AUTOSAR XML (schema 3.1.2)
package /Components/SWC_CoStopStart
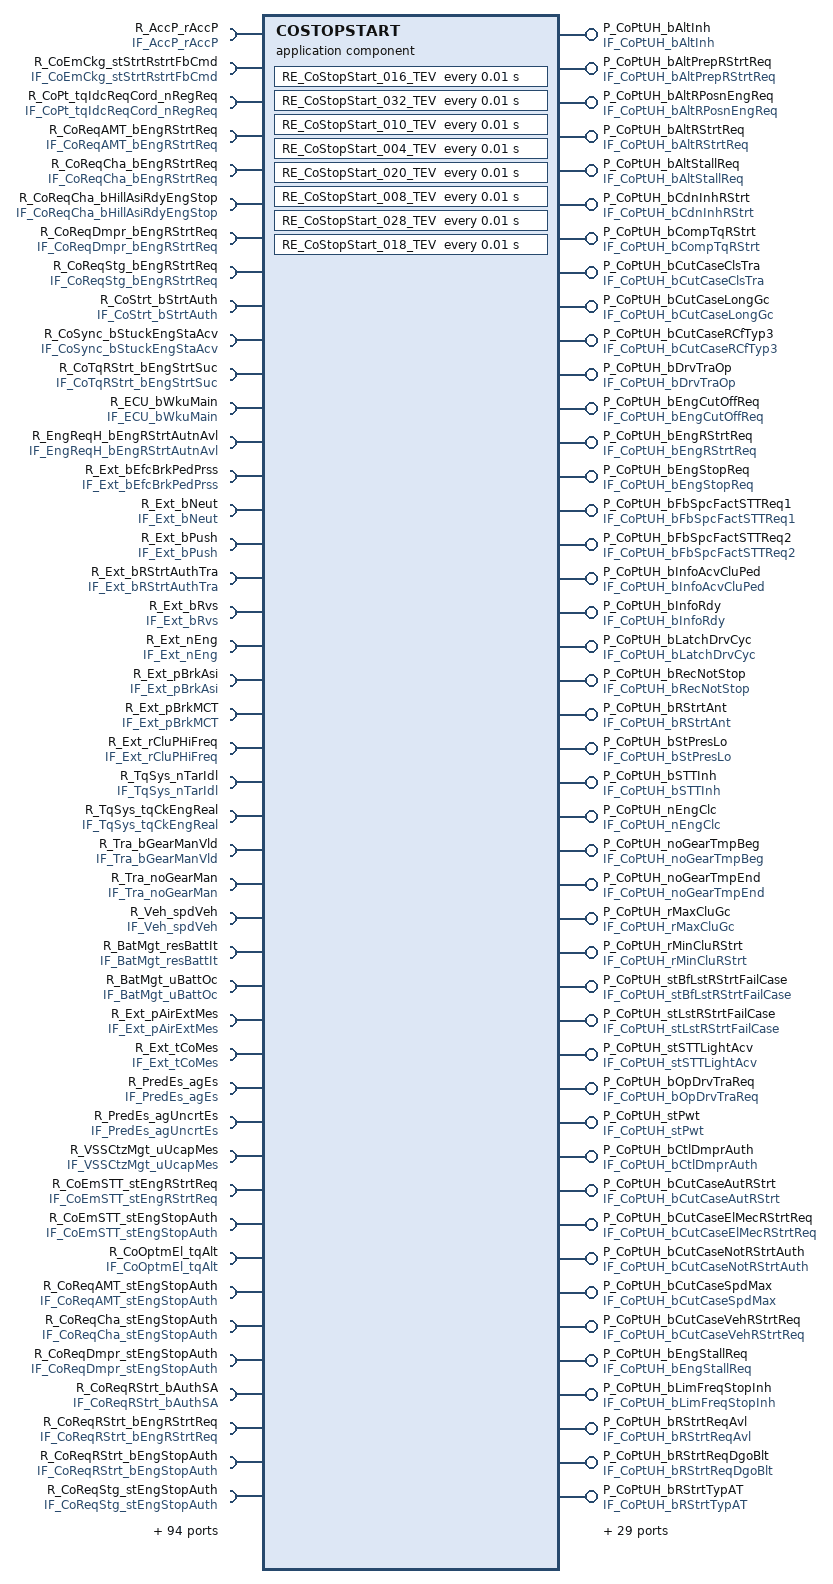
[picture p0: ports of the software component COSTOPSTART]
  application software component type COSTOPSTART
    124 x require port:
      R_AccP_rAccP: unqueued-receiver-com-spec{data-element=AccP_rAccP, init-value=ConstantValue, resync-time=0}, required-interface=IF_AccP_rAccP
      R_CoEmCkg_stStrtRstrtFbCmd: unqueued-receiver-com-spec{data-element=CoEmCkg_stStrtRstrtFbCmd, init-value=ConstantValue1, resync-time=0}, required-interface=IF_CoEmCkg_stStrtRstrtFbCmd
      R_CoPt_tqIdcReqCord_nRegReq: unqueued-receiver-com-spec{data-element=CoPt_tqIdcReqCord_nRegReq, init-value=ConstantValue3, resync-time=0}, required-interface=IF_CoPt_tqIdcReqCord_nRegReq
      R_CoReqAMT_bEngRStrtReq: unqueued-receiver-com-spec{data-element=CoReqAMT_bEngRStrtReq, init-value=CoReqAMT_bEngRStrtReq_in, resync-time=0}, required-interface=IF_CoReqAMT_bEngRStrtReq
      R_CoReqCha_bEngRStrtReq: unqueued-receiver-com-spec{data-element=CoReqCha_bEngRStrtReq, init-value=CoReqCha_bEngRStrtReq_in, resync-time=0}, required-interface=IF_CoReqCha_bEngRStrtReq
      R_CoReqCha_bHillAsiRdyEngStop: unqueued-receiver-com-spec{data-element=CoReqCha_bHillAsiRdyEngStop, init-value=CoReqCha_bHillAsiRdyEngStop_in, resync-time=0}, required-interface=IF_CoReqCha_bHillAsiRdyEngStop
      R_CoReqDmpr_bEngRStrtReq: unqueued-receiver-com-spec{data-element=CoReqDmpr_bEngRStrtReq, init-value=CoReqDmpr_bEngRStrtReq_in, resync-time=0}, required-interface=IF_CoReqDmpr_bEngRStrtReq
      R_CoReqStg_bEngRStrtReq: unqueued-receiver-com-spec{data-element=CoReqStg_bEngRStrtReq, init-value=CoReqStg_bEngRStrtReq_in, resync-time=0}, required-interface=IF_CoReqStg_bEngRStrtReq
      R_CoStrt_bStrtAuth: unqueued-receiver-com-spec{data-element=CoStrt_bStrtAuth, init-value=CoStrt_bStrtAuth_in, resync-time=0}, required-interface=IF_CoStrt_bStrtAuth
      R_CoSync_bStuckEngStaAcv: unqueued-receiver-com-spec{data-element=CoSync_bStuckEngStaAcv, init-value=CoSync_bStuckEngStaAcv_in, resync-time=0}, required-interface=IF_CoSync_bStuckEngStaAcv
      R_CoTqRStrt_bEngStrtSuc: unqueued-receiver-com-spec{data-element=CoTqRStrt_bEngStrtSuc, init-value=ConstantValue5, resync-time=0}, required-interface=IF_CoTqRStrt_bEngStrtSuc
      R_ECU_bWkuMain: unqueued-receiver-com-spec{data-element=ECU_bWkuMain, init-value=ConstantValue7, resync-time=0}, required-interface=IF_ECU_bWkuMain
      R_EngReqH_bEngRStrtAutnAvl: unqueued-receiver-com-spec{data-element=EngReqH_bEngRStrtAutnAvl, init-value=ConstantValue9, resync-time=0}, required-interface=IF_EngReqH_bEngRStrtAutnAvl
      R_Ext_bEfcBrkPedPrss: unqueued-receiver-com-spec{data-element=Ext_bEfcBrkPedPrss, init-value=Ext_bEfcBrkPedPrss_in, resync-time=0}, required-interface=IF_Ext_bEfcBrkPedPrss
      R_Ext_bNeut: unqueued-receiver-com-spec{data-element=Ext_bNeut, init-value=ConstantValue11, resync-time=0}, required-interface=IF_Ext_bNeut
      R_Ext_bPush: unqueued-receiver-com-spec{data-element=Ext_bPush, init-value=Ext_bPush_in, resync-time=0}, required-interface=IF_Ext_bPush
      R_Ext_bRStrtAuthTra: unqueued-receiver-com-spec{data-element=Ext_bRStrtAuthTra, init-value=Ext_bRStrtAuthTra_in, resync-time=0}, required-interface=IF_Ext_bRStrtAuthTra
      R_Ext_bRvs: unqueued-receiver-com-spec{data-element=Ext_bRvs, init-value=ConstantValue13, resync-time=0}, required-interface=IF_Ext_bRvs
      R_Ext_nEng: unqueued-receiver-com-spec{data-element=Ext_nEng, init-value=ConstantValue15, resync-time=0}, required-interface=IF_Ext_nEng
      R_Ext_pBrkAsi: unqueued-receiver-com-spec{data-element=Ext_pBrkAsi, init-value=Ext_pBrkAsi_in, resync-time=0}, required-interface=IF_Ext_pBrkAsi
      R_Ext_pBrkMCT: unqueued-receiver-com-spec{data-element=Ext_pBrkMCT, init-value=Ext_pBrkMCT_in, resync-time=0}, required-interface=IF_Ext_pBrkMCT
      R_Ext_rCluPHiFreq: unqueued-receiver-com-spec{data-element=Ext_rCluPHiFreq, init-value=ConstantValue17, resync-time=0}, required-interface=IF_Ext_rCluPHiFreq
      R_TqSys_nTarIdl: unqueued-receiver-com-spec{data-element=TqSys_nTarIdl, init-value=ConstantValue19, resync-time=0}, required-interface=IF_TqSys_nTarIdl
      R_TqSys_tqCkEngReal: unqueued-receiver-com-spec{data-element=TqSys_tqCkEngReal, init-value=ConstantValue21, resync-time=0}, required-interface=IF_TqSys_tqCkEngReal
      R_Tra_bGearManVld: unqueued-receiver-com-spec{data-element=Tra_bGearManVld, init-value=ConstantValue23, resync-time=0}, required-interface=IF_Tra_bGearManVld
      R_Tra_noGearMan: unqueued-receiver-com-spec{data-element=Tra_noGearMan, init-value=ConstantValue25, resync-time=0}, required-interface=IF_Tra_noGearMan
      R_Veh_spdVeh: unqueued-receiver-com-spec{data-element=Veh_spdVeh, init-value=ConstantValue27, resync-time=0}, required-interface=IF_Veh_spdVeh
      R_BatMgt_resBattIt: unqueued-receiver-com-spec{data-element=BatMgt_resBattIt, init-value=ConstantValue29, resync-time=0}, required-interface=IF_BatMgt_resBattIt
      R_BatMgt_uBattOc: unqueued-receiver-com-spec{data-element=BatMgt_uBattOc, init-value=BatMgt_uBattOc_in, resync-time=0}, required-interface=IF_BatMgt_uBattOc
      R_Ext_pAirExtMes: unqueued-receiver-com-spec{data-element=Ext_pAirExtMes, init-value=Ext_pAirExtMes_in, resync-time=0}, required-interface=IF_Ext_pAirExtMes
      R_Ext_tCoMes: unqueued-receiver-com-spec{data-element=Ext_tCoMes, init-value=ConstantValue31, resync-time=0}, required-interface=IF_Ext_tCoMes
      R_PredEs_agEs: unqueued-receiver-com-spec{data-element=PredEs_agEs, init-value=PredEs_agEs_in, resync-time=0}, required-interface=IF_PredEs_agEs
      R_PredEs_agUncrtEs: unqueued-receiver-com-spec{data-element=PredEs_agUncrtEs, init-value=PredEs_agUncrtEs_in, resync-time=0}, required-interface=IF_PredEs_agUncrtEs
      R_VSSCtzMgt_uUcapMes: unqueued-receiver-com-spec{data-element=VSSCtzMgt_uUcapMes, init-value=ConstantValue33, resync-time=0}, required-interface=IF_VSSCtzMgt_uUcapMes
      R_CoEmSTT_stEngRStrtReq: unqueued-receiver-com-spec{data-element=CoEmSTT_stEngRStrtReq, init-value=ConstantValue35, resync-time=0}, required-interface=IF_CoEmSTT_stEngRStrtReq
      R_CoEmSTT_stEngStopAuth: unqueued-receiver-com-spec{data-element=CoEmSTT_stEngStopAuth, init-value=ConstantValue37, resync-time=0}, required-interface=IF_CoEmSTT_stEngStopAuth
      R_CoOptmEl_tqAlt: unqueued-receiver-com-spec{data-element=CoOptmEl_tqAlt, init-value=CoOptmEl_tqAlt_in, resync-time=0}, required-interface=IF_CoOptmEl_tqAlt
      R_CoReqAMT_stEngStopAuth: unqueued-receiver-com-spec{data-element=CoReqAMT_stEngStopAuth, init-value=CoReqAMT_stEngStopAuth_in, resync-time=0}, required-interface=IF_CoReqAMT_stEngStopAuth
      R_CoReqCha_stEngStopAuth: unqueued-receiver-com-spec{data-element=CoReqCha_stEngStopAuth, init-value=CoReqCha_stEngStopAuth_in, resync-time=0}, required-interface=IF_CoReqCha_stEngStopAuth
      R_CoReqDmpr_stEngStopAuth: unqueued-receiver-com-spec{data-element=CoReqDmpr_stEngStopAuth, init-value=CoReqDmpr_stEngStopAuth_in, resync-time=0}, required-interface=IF_CoReqDmpr_stEngStopAuth
      R_CoReqRStrt_bAuthSA: unqueued-receiver-com-spec{data-element=CoReqRStrt_bAuthSA, init-value=CoReqRStrt_bAuthSA_in, resync-time=0}, required-interface=IF_CoReqRStrt_bAuthSA
      R_CoReqRStrt_bEngRStrtReq: unqueued-receiver-com-spec{data-element=CoReqRStrt_bEngRStrtReq, init-value=CoReqRStrt_bEngRStrtReq_in, resync-time=0}, required-interface=IF_CoReqRStrt_bEngRStrtReq
      R_CoReqRStrt_bEngStopAuth: unqueued-receiver-com-spec{data-element=CoReqRStrt_bEngStopAuth, init-value=CoReqRStrt_bEngStopAuth_in, resync-time=0}, required-interface=IF_CoReqRStrt_bEngStopAuth
      R_CoReqStg_stEngStopAuth: unqueued-receiver-com-spec{data-element=CoReqStg_stEngStopAuth, init-value=CoReqStg_stEngStopAuth_in, resync-time=0}, required-interface=IF_CoReqStg_stEngStopAuth
      R_CoReqVeh_stEngRStrtReq: unqueued-receiver-com-spec{data-element=CoReqVeh_stEngRStrtReq, init-value=ConstantValue39, resync-time=0}, required-interface=IF_CoReqVeh_stEngRStrtReq
      R_CoReqVeh_stEngStopAuth: unqueued-receiver-com-spec{data-element=CoReqVeh_stEngStopAuth, init-value=CoReqVeh_stEngStopAuth_in, resync-time=0}, required-interface=IF_CoReqVeh_stEngStopAuth
      R_CoSync_bDetNNull: unqueued-receiver-com-spec{data-element=CoSync_bDetNNull, init-value=ConstantValue41, resync-time=0}, required-interface=IF_CoSync_bDetNNull
      R_EngReqH_stEngStopAuth: unqueued-receiver-com-spec{data-element=EngReqH_stEngStopAuth, init-value=EngReqH_stEngStopAuth_in, resync-time=0}, required-interface=IF_EngReqH_stEngStopAuth
      R_Ext_pRelBrkAsi: unqueued-receiver-com-spec{data-element=Ext_pRelBrkAsi, init-value=Ext_pRelBrkAsi_in, resync-time=0}, required-interface=IF_Ext_pRelBrkAsi
      R_RvAltMgt_nRvAltMes: unqueued-receiver-com-spec{data-element=RvAltMgt_nRvAltMes, init-value=RvAltMgt_nRvAltMes_in, resync-time=0}, required-interface=IF_RvAltMgt_nRvAltMes
      R_RvAltMgt_nRvAltMv: unqueued-receiver-com-spec{data-element=RvAltMgt_nRvAltMv, init-value=RvAltMgt_nRvAltMv_in, resync-time=0}, required-interface=IF_RvAltMgt_nRvAltMv
      R_RvAltMgt_tqRstrtMaxEstim: unqueued-receiver-com-spec{data-element=RvAltMgt_tqRstrtMaxEstim, init-value=RvAltMgt_tqRstrtMaxEstim_in, resync-time=0}, required-interface=IF_RvAltMgt_tqRstrtMaxEstim
      R_Veh_stDrvAvl: unqueued-receiver-com-spec{data-element=Veh_stDrvAvl, init-value=Veh_stDrvAvl_in, resync-time=0}, required-interface=IF_Veh_stDrvAvl
      R_CoEmSTT_iElNwStop: unqueued-receiver-com-spec{data-element=CoEmSTT_iElNwStop, init-value=ConstantValue43, resync-time=0}, required-interface=IF_CoEmSTT_iElNwStop
      R_CoPtSynt_stPwt: unqueued-receiver-com-spec{data-element=CoPtSynt_stPwt, init-value=ConstantValue45, resync-time=0}, required-interface=IF_CoPtSynt_stPwt
      R_CoPtUH_bDrvTraOp: unqueued-receiver-com-spec{data-element=CoPtUH_bDrvTraOp, init-value=ConstantValue47, resync-time=0}, required-interface=IF_CoPtUH_bDrvTraOp
      R_CoSync_bAgEsCfm: unqueued-receiver-com-spec{data-element=CoSync_bAgEsCfm, init-value=CoSync_bAgEsCfm_in, resync-time=0}, required-interface=IF_CoSync_bAgEsCfm
      R_Ext_bNotAvl_resBattIt: unqueued-receiver-com-spec{data-element=Ext_bNotAvl_resBattIt, init-value=ConstantValue49, resync-time=0}, required-interface=IF_Ext_bNotAvl_resBattIt
      R_Ext_bNotAvl_uBattOc: unqueued-receiver-com-spec{data-element=Ext_bNotAvl_uBattOc, init-value=Ext_bNotAvl_uBattOc_in, resync-time=0}, required-interface=IF_Ext_bNotAvl_uBattOc
      R_Ext_tOilMes: unqueued-receiver-com-spec{data-element=Ext_tOilMes, init-value=ConstantValue51, resync-time=0}, required-interface=IF_Ext_tOilMes
      R_PredEs_nFast: unqueued-receiver-com-spec{data-element=PredEs_nFast, init-value=PredEs_nFast_in, resync-time=0}, required-interface=IF_PredEs_nFast
      R_PredRstrt_noTDC: unqueued-receiver-com-spec{data-element=PredRstrt_noTDC, init-value=PredRstrt_noTDC_in, resync-time=0}, required-interface=IF_PredRstrt_noTDC
      R_PredRstrt_tiMax2TDC: unqueued-receiver-com-spec{data-element=PredRstrt_tiMax2TDC, init-value=PredRstrt_tiMax2TDC_in, resync-time=0}, required-interface=IF_PredRstrt_tiMax2TDC
      R_RvAltMgt_tRvAltStatEstim: unqueued-receiver-com-spec{data-element=RvAltMgt_tRvAltStatEstim, init-value=ConstantValue53, resync-time=0}, required-interface=IF_RvAltMgt_tRvAltStatEstim
      R_Sync_agEng: unqueued-receiver-com-spec{data-element=Sync_agEng, init-value=Sync_agEng_in, resync-time=0}, required-interface=IF_Sync_agEng
      R_CoPtASE_stPwt: unqueued-receiver-com-spec{data-element=CoPtASE_stPwt, init-value=ConstantValue55, resync-time=0}, required-interface=IF_CoPtASE_stPwt
      R_CoPTStNew_stEng: unqueued-receiver-com-spec{data-element=CoPTStNew_stEng, init-value=ConstantValue57, resync-time=0}, required-interface=IF_CoPTStNew_stEng
      R_CoPtUH_bRStrtMchAuth: unqueued-receiver-com-spec{data-element=CoPtUH_bRStrtMchAuth, init-value=ConstantValue59, resync-time=0}, required-interface=IF_CoPtUH_bRStrtMchAuth
      R_CoPtUH_bRStrtReqAvl: unqueued-receiver-com-spec{data-element=CoPtUH_bRStrtReqAvl, init-value=ConstantValue61, resync-time=0}, required-interface=IF_CoPtUH_bRStrtReqAvl
      R_CoPtUH_stMaxRStrtReq: unqueued-receiver-com-spec{data-element=CoPtUH_stMaxRStrtReq, init-value=ConstantValue63, resync-time=0}, required-interface=IF_CoPtUH_stMaxRStrtReq
      R_CoPtUH_stPwt: unqueued-receiver-com-spec{data-element=CoPtUH_stPwt, init-value=ConstantValue65, resync-time=0}, required-interface=IF_CoPtUH_stPwt
      R_Ext_stGBxCf: unqueued-receiver-com-spec{data-element=Ext_stGBxCf, init-value=ConstantValue67, resync-time=0}, required-interface=IF_Ext_stGBxCf
      R_Ext_tOilGBx: unqueued-receiver-com-spec{data-element=Ext_tOilGBx, init-value=Ext_tOilGBx_in, resync-time=0}, required-interface=IF_Ext_tOilGBx
      R_CoPtUH_bBltStopAuth: unqueued-receiver-com-spec{data-element=CoPtUH_bBltStopAuth, init-value=ConstantValue69, resync-time=0}, required-interface=IF_CoPtUH_bBltStopAuth
      R_CoPtUH_bEngCutOffReq: unqueued-receiver-com-spec{data-element=CoPtUH_bEngCutOffReq, init-value=CoPtUH_bEngCutOffReq_in, resync-time=0}, required-interface=IF_CoPtUH_bEngCutOffReq
      R_CoPt_spdVehGearRatCord: unqueued-receiver-com-spec{data-element=CoPt_spdVehGearRatCord, init-value=ConstantValue71, resync-time=0}, required-interface=IF_CoPt_spdVehGearRatCord
      R_RvAltMgt_tqRvAltGenModMv: unqueued-receiver-com-spec{data-element=RvAltMgt_tqRvAltGenModMv, init-value=RvAltMgt_tqRvAltGenModMv_in, resync-time=0}, required-interface=IF_RvAltMgt_tqRvAltGenModMv
      R_TqLimUH_stDrivTyp: unqueued-receiver-com-spec{data-element=TqLimUH_stDrivTyp, init-value=TqLimUH_stDrivTyp_in, resync-time=0}, required-interface=IF_TqLimUH_stDrivTyp
      R_PARM_bEngRstrtAutnAvl: unqueued-receiver-com-spec{data-element=PARM_bEngRstrtAutnAvl, init-value=ConstantValue73, resync-time=0}, required-interface=IF_PARM_bEngRstrtAutnAvl
      R_Afts_stSpcFactSTTReq: unqueued-receiver-com-spec{data-element=Afts_stSpcFactSTTReq, init-value=Afts_stSpcFactSTTReq_in, resync-time=0}, required-interface=IF_Afts_stSpcFactSTTReq
      R_Ext_dstVehTotMes: unqueued-receiver-com-spec{data-element=Ext_dstVehTotMes, init-value=Ext_dstVehTotMes_in, resync-time=0}, required-interface=IF_Ext_dstVehTotMes
      R_CoPtUH_bAltRStrtReq: unqueued-receiver-com-spec{data-element=CoPtUH_bAltRStrtReq, init-value=CoPtUH_bAltRStrtReq_in, resync-time=0}, required-interface=IF_CoPtUH_bAltRStrtReq
      R_CoPtUH_bFbSpcFactSTTReq1: unqueued-receiver-com-spec{data-element=CoPtUH_bFbSpcFactSTTReq1, init-value=ConstantValue75, resync-time=0}, required-interface=IF_CoPtUH_bFbSpcFactSTTReq1
      R_CoPtUH_bStPresLo: unqueued-receiver-com-spec{data-element=CoPtUH_bStPresLo, init-value=CoPtUH_bStPresLo_in, resync-time=0}, required-interface=IF_CoPtUH_bStPresLo
      R_CoTqRStrt_bTraTqAuthRaw: unqueued-receiver-com-spec{data-element=CoTqRStrt_bTraTqAuthRaw, init-value=CoTqRStrt_bTraTqAuthRaw_in, resync-time=0}, required-interface=IF_CoTqRStrt_bTraTqAuthRaw
      R_Cha_stEPB: unqueued-receiver-com-spec{data-element=Cha_stEPB, init-value=Cha_stEPB_in, resync-time=0}, required-interface=IF_Cha_stEPB
      R_CoPtUH_bOpDrvTraReq: unqueued-receiver-com-spec{data-element=CoPtUH_bOpDrvTraReq, init-value=CoPtUH_bOpDrvTraReq_in, resync-time=0}, required-interface=IF_CoPtUH_bOpDrvTraReq
      R_CoPtUH_bSTTInh: unqueued-receiver-com-spec{data-element=CoPtUH_bSTTInh, init-value=CoPtUH_bSTTInh_in, resync-time=0}, required-interface=IF_CoPtUH_bSTTInh
      R_CoPtUH_stSTTLightAcv: unqueued-receiver-com-spec{data-element=CoPtUH_stSTTLightAcv, init-value=ConstantValue77, resync-time=0}, required-interface=IF_CoPtUH_stSTTLightAcv
      R_EngReqH_bEngRunReq: unqueued-receiver-com-spec{data-element=EngReqH_bEngRunReq, init-value=EngReqH_bEngRunReq_in, resync-time=0}, required-interface=IF_EngReqH_bEngRunReq
      R_Ext_stTraTypCf: unqueued-receiver-com-spec{data-element=Ext_stTraTypCf, init-value=ConstantValue79, resync-time=0}, required-interface=IF_Ext_stTraTypCf
      R_CoReqCha_bUncrtSlopStab: unqueued-receiver-com-spec{data-element=CoReqCha_bUncrtSlopStab, init-value=CoReqCha_bUncrtSlopStab_in, resync-time=0}, required-interface=IF_CoReqCha_bUncrtSlopStab
      R_CoReqCha_rSlopStab: unqueued-receiver-com-spec{data-element=CoReqCha_rSlopStab, init-value=CoReqCha_rSlopStab_in, resync-time=0}, required-interface=IF_CoReqCha_rSlopStab
      R_CoReqCha_stEngRStrtInh: unqueued-receiver-com-spec{data-element=CoReqCha_stEngRStrtInh, init-value=ConstantValue81, resync-time=0}, required-interface=IF_CoReqCha_stEngRStrtInh
      R_Afts_bRstMemCoReqRStrt: unqueued-receiver-com-spec{data-element=Afts_bRstMemCoReqRStrt, init-value=Afts_bRstMemCoReqRStrt_in, resync-time=0}, required-interface=IF_Afts_bRstMemCoReqRStrt
      R_CoPtUH_bRstrtCritAuth: unqueued-receiver-com-spec{data-element=CoPtUH_bRstrtCritAuth, init-value=CoPtUH_bRstrtCritAuth_in, resync-time=0}, required-interface=IF_CoPtUH_bRstrtCritAuth
      R_CoOptmEl_stElEProv: unqueued-receiver-com-spec{data-element=CoOptmEl_stElEProv, init-value=CoOptmEl_stElEProv_in, resync-time=0}, required-interface=IF_CoOptmEl_stElEProv
      R_Afts_bInhIniRunReq: unqueued-receiver-com-spec{data-element=Afts_bInhIniRunReq, init-value=Afts_bInhIniRunReq_in, resync-time=0}, required-interface=IF_Afts_bInhIniRunReq
      R_Ext_posnGBxLev: unqueued-receiver-com-spec{data-element=Ext_posnGBxLev, init-value=Ext_posnGBxLev_in, resync-time=0}, required-interface=IF_Ext_posnGBxLev
      R_CoPtUH_bInhHiSpdAltRstrtReq: unqueued-receiver-com-spec{data-element=CoPtUH_bInhHiSpdAltRstrtReq, init-value=ConstantValue83, resync-time=0}, required-interface=IF_CoPtUH_bInhHiSpdAltRstrtReq
      R_Ext_spdVehSecu: unqueued-receiver-com-spec{data-element=Ext_spdVehSecu, init-value=Ext_spdVehSecu_in, resync-time=0}, required-interface=IF_Ext_spdVehSecu
      R_CoPtUH_bCompTqRStrt: unqueued-receiver-com-spec{data-element=CoPtUH_bCompTqRStrt, init-value=ConstantValue85, resync-time=0}, required-interface=IF_CoPtUH_bCompTqRStrt
      R_Sfty_bInhEngStopSTTReq: unqueued-receiver-com-spec{data-element=Sfty_bInhEngStopSTTReq, init-value=Sfty_bInhEngStopSTTReq_in, resync-time=0}, required-interface=IF_Sfty_bInhEngStopSTTReq
      R_Ext_tAir: unqueued-receiver-com-spec{data-element=Ext_tAir, init-value=ConstantValue87, resync-time=0}, required-interface=IF_Ext_tAir
      R_CoPtUH_bEngRstrtClsCluCdn: unqueued-receiver-com-spec{data-element=CoPtUH_bEngRstrtClsCluCdn, init-value=ConstantValue89, resync-time=0}, required-interface=IF_CoPtUH_bEngRstrtClsCluCdn
      R_CoReqRStrt_stRStrtTyp: unqueued-receiver-com-spec{data-element=CoReqRStrt_stRStrtTyp, init-value=CoReqRStrt_stRStrtTyp_in, resync-time=0}, required-interface=IF_CoReqRStrt_stRStrtTyp
      R_Tra_stGBxMod: unqueued-receiver-com-spec{data-element=Tra_stGBxMod, init-value=Tra_stGBxMod_in, resync-time=0}, required-interface=IF_Tra_stGBxMod
      R_Tra_noEgdGear: unqueued-receiver-com-spec{data-element=Tra_noEgdGear, init-value=Tra_noEgdGear_in, resync-time=0}, required-interface=IF_Tra_noEgdGear
      R_Tra_noTarGear: unqueued-receiver-com-spec{data-element=Tra_noTarGear, init-value=Tra_noTarGear_in, resync-time=0}, required-interface=IF_Tra_noTarGear
      R_FRM_bAcvCutCoPtUH: required-interface=FunctionInhibition
      R_FRM_bAcvCutTotCoPtUH: required-interface=FunctionInhibition
      R_FRM_bAcvRStrtCoPtUH: required-interface=FunctionInhibition
      R_FRM_bAcvRunCoPtUH: required-interface=FunctionInhibition
      R_FRM_bAcvSTTLitCoPtUH: required-interface=FunctionInhibition
      R_FRM_bInhCluPCoPtUH: required-interface=FunctionInhibition
      R_FRM_bInhNeutCoPtUH: required-interface=FunctionInhibition
      R_FRM_bInhPushCoPtUH: required-interface=FunctionInhibition
      R_FRM_bInhspdVehCoPtUH: required-interface=FunctionInhibition
      R_FRM_bInhStopCoPtUH: required-interface=FunctionInhibition
      R_FRM_bAcvFastRStrtCoPtUH: required-interface=FunctionInhibition
      R_FRM_bInhCtlDmprAuth: required-interface=FunctionInhibition
      R_FRM_bInhDgoBltCoPtUH: required-interface=FunctionInhibition
      R_FRM_bInhDgoCluNeutCoPtUH: required-interface=FunctionInhibition
      R_FRM_bInhRelBrkAsiCoPtUH: required-interface=FunctionInhibition
    69 x provide port:
      P_CoPtUH_bAltInh: unqueued-sender-com-spec{data-element=CoPtUH_bAltInh, can-invalidate=false, init-value=CoPtUH_bAltInh_out}, provided-interface=IF_CoPtUH_bAltInh
      P_CoPtUH_bAltPrepRStrtReq: unqueued-sender-com-spec{data-element=CoPtUH_bAltPrepRStrtReq, can-invalidate=false, init-value=CoPtUH_bAltPrepRStrtReq_out}, provided-interface=IF_CoPtUH_bAltPrepRStrtReq
      P_CoPtUH_bAltRPosnEngReq: unqueued-sender-com-spec{data-element=CoPtUH_bAltRPosnEngReq, can-invalidate=false, init-value=CoPtUH_bAltRPosnEngReq_out}, provided-interface=IF_CoPtUH_bAltRPosnEngReq
      P_CoPtUH_bAltRStrtReq: unqueued-sender-com-spec{data-element=CoPtUH_bAltRStrtReq, can-invalidate=false, init-value=CoPtUH_bAltRStrtReq_out}, provided-interface=IF_CoPtUH_bAltRStrtReq
      P_CoPtUH_bAltStallReq: unqueued-sender-com-spec{data-element=CoPtUH_bAltStallReq, can-invalidate=false, init-value=CoPtUH_bAltStallReq_out}, provided-interface=IF_CoPtUH_bAltStallReq
      P_CoPtUH_bCdnInhRStrt: unqueued-sender-com-spec{data-element=CoPtUH_bCdnInhRStrt, can-invalidate=false, init-value=CoPtUH_bCdnInhRStrt_out}, provided-interface=IF_CoPtUH_bCdnInhRStrt
      P_CoPtUH_bCompTqRStrt: unqueued-sender-com-spec{data-element=CoPtUH_bCompTqRStrt, can-invalidate=false, init-value=ConstantValue91}, provided-interface=IF_CoPtUH_bCompTqRStrt
      P_CoPtUH_bCutCaseClsTra: unqueued-sender-com-spec{data-element=CoPtUH_bCutCaseClsTra, can-invalidate=false, init-value=CoPtUH_bCutCaseClsTra_out}, provided-interface=IF_CoPtUH_bCutCaseClsTra
      P_CoPtUH_bCutCaseLongGc: unqueued-sender-com-spec{data-element=CoPtUH_bCutCaseLongGc, can-invalidate=false, init-value=CoPtUH_bCutCaseLongGc_out}, provided-interface=IF_CoPtUH_bCutCaseLongGc
      P_CoPtUH_bCutCaseRCfTyp3: unqueued-sender-com-spec{data-element=CoPtUH_bCutCaseRCfTyp3, can-invalidate=false, init-value=CoPtUH_bCutCaseRCfTyp3_out}, provided-interface=IF_CoPtUH_bCutCaseRCfTyp3
      P_CoPtUH_bDrvTraOp: unqueued-sender-com-spec{data-element=CoPtUH_bDrvTraOp, can-invalidate=false, init-value=ConstantValue93}, provided-interface=IF_CoPtUH_bDrvTraOp
      P_CoPtUH_bEngCutOffReq: unqueued-sender-com-spec{data-element=CoPtUH_bEngCutOffReq, can-invalidate=false, init-value=CoPtUH_bEngCutOffReq_out}, provided-interface=IF_CoPtUH_bEngCutOffReq
      P_CoPtUH_bEngRStrtReq: unqueued-sender-com-spec{data-element=CoPtUH_bEngRStrtReq, can-invalidate=false, init-value=CoPtUH_bEngRStrtReq_out}, provided-interface=IF_CoPtUH_bEngRStrtReq
      P_CoPtUH_bEngStopReq: unqueued-sender-com-spec{data-element=CoPtUH_bEngStopReq, can-invalidate=false, init-value=CoPtUH_bEngStopReq_out}, provided-interface=IF_CoPtUH_bEngStopReq
      P_CoPtUH_bFbSpcFactSTTReq1: unqueued-sender-com-spec{data-element=CoPtUH_bFbSpcFactSTTReq1, can-invalidate=false, init-value=ConstantValue95}, provided-interface=IF_CoPtUH_bFbSpcFactSTTReq1
      P_CoPtUH_bFbSpcFactSTTReq2: unqueued-sender-com-spec{data-element=CoPtUH_bFbSpcFactSTTReq2, can-invalidate=false, init-value=ConstantValue97}, provided-interface=IF_CoPtUH_bFbSpcFactSTTReq2
      P_CoPtUH_bInfoAcvCluPed: unqueued-sender-com-spec{data-element=CoPtUH_bInfoAcvCluPed, can-invalidate=false, init-value=CoPtUH_bInfoAcvCluPed_out}, provided-interface=IF_CoPtUH_bInfoAcvCluPed
      P_CoPtUH_bInfoRdy: unqueued-sender-com-spec{data-element=CoPtUH_bInfoRdy, can-invalidate=false, init-value=CoPtUH_bInfoRdy_out}, provided-interface=IF_CoPtUH_bInfoRdy
      P_CoPtUH_bLatchDrvCyc: unqueued-sender-com-spec{data-element=CoPtUH_bLatchDrvCyc, can-invalidate=false, init-value=CoPtUH_bLatchDrvCyc_out}, provided-interface=IF_CoPtUH_bLatchDrvCyc
      P_CoPtUH_bRecNotStop: unqueued-sender-com-spec{data-element=CoPtUH_bRecNotStop, can-invalidate=false, init-value=CoPtUH_bRecNotStop_out}, provided-interface=IF_CoPtUH_bRecNotStop
      P_CoPtUH_bRStrtAnt: unqueued-sender-com-spec{data-element=CoPtUH_bRStrtAnt, can-invalidate=false, init-value=CoPtUH_bRStrtAnt_out}, provided-interface=IF_CoPtUH_bRStrtAnt
      P_CoPtUH_bStPresLo: unqueued-sender-com-spec{data-element=CoPtUH_bStPresLo, can-invalidate=false, init-value=CoPtUH_bStPresLo_out}, provided-interface=IF_CoPtUH_bStPresLo
      P_CoPtUH_bSTTInh: unqueued-sender-com-spec{data-element=CoPtUH_bSTTInh, can-invalidate=false, init-value=CoPtUH_bSTTInh_out}, provided-interface=IF_CoPtUH_bSTTInh
      P_CoPtUH_nEngClc: unqueued-sender-com-spec{data-element=CoPtUH_nEngClc, can-invalidate=false, init-value=CoPtUH_nEngClc_out}, provided-interface=IF_CoPtUH_nEngClc
      P_CoPtUH_noGearTmpBeg: unqueued-sender-com-spec{data-element=CoPtUH_noGearTmpBeg, can-invalidate=false, init-value=CoPtUH_noGearTmpBeg_out}, provided-interface=IF_CoPtUH_noGearTmpBeg
      P_CoPtUH_noGearTmpEnd: unqueued-sender-com-spec{data-element=CoPtUH_noGearTmpEnd, can-invalidate=false, init-value=CoPtUH_noGearTmpEnd_out}, provided-interface=IF_CoPtUH_noGearTmpEnd
      P_CoPtUH_rMaxCluGc: unqueued-sender-com-spec{data-element=CoPtUH_rMaxCluGc, can-invalidate=false, init-value=CoPtUH_rMaxCluGc_out}, provided-interface=IF_CoPtUH_rMaxCluGc
      P_CoPtUH_rMinCluRStrt: unqueued-sender-com-spec{data-element=CoPtUH_rMinCluRStrt, can-invalidate=false, init-value=CoPtUH_rMinCluRStrt_out}, provided-interface=IF_CoPtUH_rMinCluRStrt
      P_CoPtUH_stBfLstRStrtFailCase: unqueued-sender-com-spec{data-element=CoPtUH_stBfLstRStrtFailCase, can-invalidate=false, init-value=CoPtUH_stBfLstRStrtFailCase_out}, provided-interface=IF_CoPtUH_stBfLstRStrtFailCase
      P_CoPtUH_stLstRStrtFailCase: unqueued-sender-com-spec{data-element=CoPtUH_stLstRStrtFailCase, can-invalidate=false, init-value=CoPtUH_stLstRStrtFailCase_out}, provided-interface=IF_CoPtUH_stLstRStrtFailCase
      P_CoPtUH_stSTTLightAcv: unqueued-sender-com-spec{data-element=CoPtUH_stSTTLightAcv, can-invalidate=false, init-value=ConstantValue99}, provided-interface=IF_CoPtUH_stSTTLightAcv
      P_CoPtUH_bOpDrvTraReq: unqueued-sender-com-spec{data-element=CoPtUH_bOpDrvTraReq, can-invalidate=false, init-value=CoPtUH_bOpDrvTraReq_out}, provided-interface=IF_CoPtUH_bOpDrvTraReq
      P_CoPtUH_stPwt: unqueued-sender-com-spec{data-element=CoPtUH_stPwt, can-invalidate=false, init-value=ConstantValue101}, provided-interface=IF_CoPtUH_stPwt
      P_CoPtUH_bCtlDmprAuth: unqueued-sender-com-spec{data-element=CoPtUH_bCtlDmprAuth, can-invalidate=false, init-value=CoPtUH_bCtlDmprAuth_out}, provided-interface=IF_CoPtUH_bCtlDmprAuth
      P_CoPtUH_bCutCaseAutRStrt: unqueued-sender-com-spec{data-element=CoPtUH_bCutCaseAutRStrt, can-invalidate=false, init-value=CoPtUH_bCutCaseAutRStrt_out}, provided-interface=IF_CoPtUH_bCutCaseAutRStrt
      P_CoPtUH_bCutCaseElMecRStrtReq: unqueued-sender-com-spec{data-element=CoPtUH_bCutCaseElMecRStrtReq, can-invalidate=false, init-value=CoPtUH_bCutCaseElMecRStrtReq_out}, provided-interface=IF_CoPtUH_bCutCaseElMecRStrtReq
      P_CoPtUH_bCutCaseNotRStrtAuth: unqueued-sender-com-spec{data-element=CoPtUH_bCutCaseNotRStrtAuth, can-invalidate=false, init-value=CoPtUH_bCutCaseNotRStrtAuth_out}, provided-interface=IF_CoPtUH_bCutCaseNotRStrtAuth
      P_CoPtUH_bCutCaseSpdMax: unqueued-sender-com-spec{data-element=CoPtUH_bCutCaseSpdMax, can-invalidate=false, init-value=CoPtUH_bCutCaseSpdMax_out}, provided-interface=IF_CoPtUH_bCutCaseSpdMax
      P_CoPtUH_bCutCaseVehRStrtReq: unqueued-sender-com-spec{data-element=CoPtUH_bCutCaseVehRStrtReq, can-invalidate=false, init-value=CoPtUH_bCutCaseVehRStrtReq_out}, provided-interface=IF_CoPtUH_bCutCaseVehRStrtReq
      P_CoPtUH_bEngStallReq: unqueued-sender-com-spec{data-element=CoPtUH_bEngStallReq, can-invalidate=false, init-value=ConstantValue103}, provided-interface=IF_CoPtUH_bEngStallReq
      P_CoPtUH_bLimFreqStopInh: unqueued-sender-com-spec{data-element=CoPtUH_bLimFreqStopInh, can-invalidate=false, init-value=ConstantValue105}, provided-interface=IF_CoPtUH_bLimFreqStopInh
      P_CoPtUH_bRStrtReqAvl: unqueued-sender-com-spec{data-element=CoPtUH_bRStrtReqAvl, can-invalidate=false, init-value=ConstantValue107}, provided-interface=IF_CoPtUH_bRStrtReqAvl
      P_CoPtUH_bRStrtReqDgoBlt: unqueued-sender-com-spec{data-element=CoPtUH_bRStrtReqDgoBlt, can-invalidate=false, init-value=ConstantValue109}, provided-interface=IF_CoPtUH_bRStrtReqDgoBlt
      P_CoPtUH_bRStrtTypAT: unqueued-sender-com-spec{data-element=CoPtUH_bRStrtTypAT, can-invalidate=false, init-value=CoPtUH_bRStrtTypAT_out}, provided-interface=IF_CoPtUH_bRStrtTypAT
      P_CoPtUH_bTestPrvtBltAcv: unqueued-sender-com-spec{data-element=CoPtUH_bTestPrvtBltAcv, can-invalidate=false, init-value=CoPtUH_bTestPrvtBltAcv_out}, provided-interface=IF_CoPtUH_bTestPrvtBltAcv
      P_CoPtUH_bVSSNwAcvAuth: unqueued-sender-com-spec{data-element=CoPtUH_bVSSNwAcvAuth, can-invalidate=false, init-value=CoPtUH_bVSSNwAcvAuth_out}, provided-interface=IF_CoPtUH_bVSSNwAcvAuth
      P_CoPtUH_stMaxRStrtReq: unqueued-sender-com-spec{data-element=CoPtUH_stMaxRStrtReq, can-invalidate=false, init-value=ConstantValue111}, provided-interface=IF_CoPtUH_stMaxRStrtReq
      P_CoPtUH_stTypSTTNotAvl: unqueued-sender-com-spec{data-element=CoPtUH_stTypSTTNotAvl, can-invalidate=false, init-value=ConstantValue113}, provided-interface=IF_CoPtUH_stTypSTTNotAvl
      P_CoPtUH_tiCmplStop: unqueued-sender-com-spec{data-element=CoPtUH_tiCmplStop, can-invalidate=false, init-value=ConstantValue115}, provided-interface=IF_CoPtUH_tiCmplStop
      P_CoReqRStrt_bAuthSA: unqueued-sender-com-spec{data-element=CoReqRStrt_bAuthSA, can-invalidate=false, init-value=CoReqRStrt_bAuthSA_out}, provided-interface=IF_CoReqRStrt_bAuthSA
      P_CoReqRStrt_bEngRStrtReq: unqueued-sender-com-spec{data-element=CoReqRStrt_bEngRStrtReq, can-invalidate=false, init-value=CoReqRStrt_bEngRStrtReq_out}, provided-interface=IF_CoReqRStrt_bEngRStrtReq
      P_CoReqRStrt_bEngStopAuth: unqueued-sender-com-spec{data-element=CoReqRStrt_bEngStopAuth, can-invalidate=false, init-value=CoReqRStrt_bEngStopAuth_out}, provided-interface=IF_CoReqRStrt_bEngStopAuth
      P_CoReqRStrt_stRStrtTyp: unqueued-sender-com-spec{data-element=CoReqRStrt_stRStrtTyp, can-invalidate=false, init-value=CoReqRStrt_stRStrtTyp_out}, provided-interface=IF_CoReqRStrt_stRStrtTyp
      P_CoPtUH_bCutCaseDgoBlt: unqueued-sender-com-spec{data-element=CoPtUH_bCutCaseDgoBlt, can-invalidate=false, init-value=CoPtUH_bCutCaseDgoBlt_out}, provided-interface=IF_CoPtUH_bCutCaseDgoBlt
      P_CoPtUH_bCutCaseRStrtReqForc: unqueued-sender-com-spec{data-element=CoPtUH_bCutCaseRStrtReqForc, can-invalidate=false, init-value=CoPtUH_bCutCaseRStrtReqForc_out}, provided-interface=IF_CoPtUH_bCutCaseRStrtReqForc
      P_CoPtUH_stBfBfLstRStrtFail: unqueued-sender-com-spec{data-element=CoPtUH_stBfBfLstRStrtFail, can-invalidate=false, init-value=CoPtUH_stBfBfLstRStrtFail_out}, provided-interface=IF_CoPtUH_stBfBfLstRStrtFail
      P_CoPtUH_bBltStopAuth: unqueued-sender-com-spec{data-element=CoPtUH_bBltStopAuth, can-invalidate=false, init-value=ConstantValue117}, provided-interface=IF_CoPtUH_bBltStopAuth
      P_CoPtUH_stTestPosClu: unqueued-sender-com-spec{data-element=CoPtUH_stTestPosClu, can-invalidate=false, init-value=CoPtUH_stTestPosClu_out}, provided-interface=IF_CoPtUH_stTestPosClu
      P_CoPtUH_stAftsRStrtSuc: unqueued-sender-com-spec{data-element=CoPtUH_stAftsRStrtSuc, can-invalidate=false, init-value=CoPtUH_stAftsRStrtSuc_out}, provided-interface=IF_CoPtUH_stAftsRStrtSuc
      P_CoPtUH_stFbSpcFactRStrtSuc: unqueued-sender-com-spec{data-element=CoPtUH_stFbSpcFactRStrtSuc, can-invalidate=false, init-value=CoPtUH_stFbSpcFactRStrtSuc_out}, provided-interface=IF_CoPtUH_stFbSpcFactRStrtSuc
      P_CoPtUH_tiNbRstrtFreqLim: unqueued-sender-com-spec{data-element=CoPtUH_tiNbRstrtFreqLim, can-invalidate=false, init-value=CoPtUH_tiNbRstrtFreqLim_out}, provided-interface=IF_CoPtUH_tiNbRstrtFreqLim
      P_CoPtUH_bRStrtMchAuth: unqueued-sender-com-spec{data-element=CoPtUH_bRStrtMchAuth, can-invalidate=false, init-value=ConstantValue119}, provided-interface=IF_CoPtUH_bRStrtMchAuth
      P_CoPtUH_bStopAuthSlop: unqueued-sender-com-spec{data-element=CoPtUH_bStopAuthSlop, can-invalidate=false, init-value=CoPtUH_bStopAuthSlop_out}, provided-interface=IF_CoPtUH_bStopAuthSlop
      P_CoReqRStrt_bNotBlsVehReq: unqueued-sender-com-spec{data-element=CoReqRStrt_bNotBlsVehReq, can-invalidate=false, init-value=CoReqRStrt_bNotBlsVehReq_out}, provided-interface=IF_CoReqRStrt_bNotBlsVehReq
      P_CoReqRStrt_bRstrtAuth: unqueued-sender-com-spec{data-element=CoReqRStrt_bRstrtAuth, can-invalidate=false, init-value=CoReqRStrt_bRstrtAuth_out}, provided-interface=IF_CoReqRStrt_bRstrtAuth
      P_CoPtUH_bRstrtCritAuth: unqueued-sender-com-spec{data-element=CoPtUH_bRstrtCritAuth, can-invalidate=false, init-value=CoPtUH_bRstrtCritAuth_out}, provided-interface=IF_CoPtUH_bRstrtCritAuth
      P_CoPtUH_bEngRstrtClsCluCdn: unqueued-sender-com-spec{data-element=CoPtUH_bEngRstrtClsCluCdn, can-invalidate=false, init-value=ConstantValue121}, provided-interface=IF_CoPtUH_bEngRstrtClsCluCdn
      P_CoPtUH_bInhHiSpdAltRstrtReq: unqueued-sender-com-spec{data-element=CoPtUH_bInhHiSpdAltRstrtReq, can-invalidate=false, init-value=ConstantValue123}, provided-interface=IF_CoPtUH_bInhHiSpdAltRstrtReq
      P_CoPtUH_pRelBrkAsi: unqueued-sender-com-spec{data-element=CoPtUH_pRelBrkAsi, can-invalidate=false, init-value=CoPtUH_pRelBrkAsi_out}, provided-interface=IF_CoPtUH_pRelBrkAsi
    11 x require port:
      R_CoPtUH_Blt: required-interface=DiagnosticMonitor
      R_CoPtUH_CutReq: required-interface=DiagnosticMonitor
      R_CoPtUH_ORngGcClu: required-interface=DiagnosticMonitor
      R_CoPtUH_ORngGcNeut: required-interface=DiagnosticMonitor
      R_CoPtUH_ORngGearEnaClu: required-interface=DiagnosticMonitor
      R_CoPtUH_ORngGearNeut: required-interface=DiagnosticMonitor
      R_CoPtUH_ORngGcMinClu: required-interface=DiagnosticMonitor
      R_CoPtUH_ORngGearMinClu: required-interface=DiagnosticMonitor
      R_CoPtUH_LgEngRStrtInh: required-interface=DiagnosticMonitor
      R_UCE_stWkuMainRelSt: required-interface=IF_UCE_stWkuMainRelSt
      R_EcuM_CurrentMode: required-interface=EcuM_CurrentMode
    provide port P_CoStopStart_AftsNvramWrite_1: server-com-spec{operation=CoStopStart_AftsNvramWrite_1, queue-length=1}, provided-interface=IF_CoStopStart_AftsNvramWrite_1
    provide port P_CoStopStart_AftsNvramRead_1: server-com-spec{operation=CoStopStart_AftsNvramRead_1, queue-length=1}, provided-interface=IF_CoStopStart_AftsNvramRead_1
    provide port P_CoStopStart_AftsNvramReset_1: server-com-spec{operation=CoStopStart_AftsNvramReset_1, queue-length=1}, provided-interface=IF_CoStopStart_AftsNvramReset_1
    require port R_CoPtUH_bEngStopReq: unqueued-receiver-com-spec{data-element=CoPtUH_bEngStopReq, init-value=CoPtUH_bEngStopReq_out, resync-time=0}, required-interface=IF_CoPtUH_bEngStopReq
    provide port P_CoPtUH_bAcvGSINeut: unqueued-sender-com-spec{data-element=CoPtUH_bAcvGSINeut, can-invalidate=false, init-value=CoPtUH_bAcvGSINeut_Cst}, provided-interface=IF_CoPtUH_bAcvGSINeut
    require port R_TqLimUH_bAcvUnBlsEng: unqueued-receiver-com-spec{data-element=TqLimUH_bAcvUnBlsEng, init-value=TqLimUH_bAcvUnBlsEng_Cst, resync-time=0}, required-interface=IF_TqLimUH_bAcvUnBlsEng
    require port R_CoPt_bInhEngStopProtManClu: unqueued-receiver-com-spec{data-element=CoPt_bInhEngStopProtManClu, init-value=CoPt_bInhEngStopProtManClu_Cst, resync-time=0}, required-interface=IF_CoPt_bInhEngStopProtManClu
  228 x constant specification:
    Afts_bInhIniRunReq_in
      value:
        boolean literal Afts_bInhIniRunReq_in: type=DT_Afts_bInhIniRunReq, value=false
    Afts_bRstMemCoReqRStrt_in
      value:
        boolean literal Afts_bRstMemCoReqRStrt_in: type=DT_Afts_bRstMemCoReqRStrt, value=false
    Afts_stSpcFactSTTReq_in
      value:
        integer literal Afts_stSpcFactSTTReq_in: type=DT_Afts_stSpcFactSTTReq, value=0
    BatMgt_uBattOc_in
      value:
        integer literal BatMgt_uBattOc_in: type=DT_BatMgt_uBattOc, value=1408
    Cha_stEPB_in
      value:
        integer literal Cha_stEPB_in: type=DT_Cha_stEPB, value=0
    CoCut_bElMecIntrRstrt_Cst
      value:
        boolean literal CoCut_bElMecIntrRstrt_Cst: type=DT_CoCut_bElMecIntrRstrt, value=false
    CoCut_bRstrtFail_Cst
      value:
        boolean literal CoCut_bRstrtFail_Cst: type=DT_CoCut_bRstrtFail, value=false
    CoCut_ctForcRstrtFail_Cst
      value:
        integer literal CoCut_ctForcRstrtFail_Cst: type=DT_CoCut_ctForcRstrtFail, value=0
    CoCut_ctRstrtFail_Cst
      value:
        integer literal CoCut_ctRstrtFail_Cst: type=DT_CoCut_ctRstrtFail, value=0
    ConstantValue
      value:
        integer literal ConstantValue: type=DT_AccP_rAccP, value=0
    ConstantValue1
      value:
        integer literal ConstantValue1: type=DT_CoEmCkg_stStrtRstrtFbCmd, value=0
    ConstantValue101
      value:
        integer literal ConstantValue101: type=DT_CoPtUH_stPwt, value=1
    ConstantValue103
      value:
        boolean literal ConstantValue103: type=DT_CoPtUH_bEngStallReq, value=false
    ConstantValue105
      value:
        boolean literal ConstantValue105: type=DT_CoPtUH_bLimFreqStopInh, value=false
    ConstantValue107
      value:
        boolean literal ConstantValue107: type=DT_CoPtUH_bRStrtReqAvl, value=false
    ConstantValue109
      value:
        boolean literal ConstantValue109: type=DT_CoPtUH_bRStrtReqDgoBlt, value=false
    ConstantValue11
      value:
        boolean literal ConstantValue11: type=DT_Ext_bNeut, value=false
    ConstantValue111
      value:
        integer literal ConstantValue111: type=DT_CoPtUH_stMaxRStrtReq, value=0
    ConstantValue113
      value:
        integer literal ConstantValue113: type=DT_CoPtUH_stTypSTTNotAvl, value=0
    ConstantValue115
      value:
        integer literal ConstantValue115: type=DT_CoPtUH_tiCmplStop, value=0
    ConstantValue117
      value:
        boolean literal ConstantValue117: type=DT_CoPtUH_bBltStopAuth, value=false
    ConstantValue119
      value:
        boolean literal ConstantValue119: type=DT_CoPtUH_bRStrtMchAuth, value=false
    ConstantValue121
      value:
        boolean literal ConstantValue121: type=DT_CoPtUH_bEngRstrtClsCluCdn, value=false
    ConstantValue123
      value:
        boolean literal ConstantValue123: type=DT_CoPtUH_bInhHiSpdAltRstrtReq, value=false
    ConstantValue13
      value:
        boolean literal ConstantValue13: type=DT_Ext_bRvs, value=false
    ConstantValue15
      value:
        integer literal ConstantValue15: type=DT_Ext_nEng, value=0
    ConstantValue17
      value:
        integer literal ConstantValue17: type=DT_Ext_rCluPHiFreq, value=0
    ConstantValue19
      value:
        integer literal ConstantValue19: type=DT_TqSys_nTarIdl, value=0
    ConstantValue21
      value:
        integer literal ConstantValue21: type=DT_TqSys_tqCkEngReal, value=0
    ConstantValue23
      value:
        boolean literal ConstantValue23: type=DT_Tra_bGearManVld, value=false
    ConstantValue25
      value:
        integer literal ConstantValue25: type=DT_Tra_noGearMan, value=0
    ConstantValue27
      value:
        integer literal ConstantValue27: type=DT_Veh_spdVeh, value=0
    ConstantValue29
      value:
        integer literal ConstantValue29: type=DT_BatMgt_resBattIt, value=0
    ConstantValue3
      value:
        integer literal ConstantValue3: type=DT_CoPt_tqIdcReqCord_nRegReq, value=0
    ConstantValue31
      value:
        integer literal ConstantValue31: type=DT_Ext_tCoMes, value=20
    ConstantValue33
      value:
        integer literal ConstantValue33: type=DT_VSSCtzMgt_uUcapMes, value=0
    ConstantValue35
      value:
        integer literal ConstantValue35: type=DT_CoEmSTT_stEngRStrtReq, value=0
    ConstantValue37
      value:
        integer literal ConstantValue37: type=DT_CoEmSTT_stEngStopAuth, value=1
    ConstantValue39
      value:
        integer literal ConstantValue39: type=DT_CoReqVeh_stEngRStrtReq, value=0
    ConstantValue41
      value:
        boolean literal ConstantValue41: type=DT_CoSync_bDetNNull, value=false
    ConstantValue43
      value:
        integer literal ConstantValue43: type=DT_CoEmSTT_iElNwStop, value=40
    ConstantValue45
      value:
        integer literal ConstantValue45: type=DT_CoPtSynt_stPwt, value=1
    ConstantValue47
      value:
        boolean literal ConstantValue47: type=DT_CoPtUH_bDrvTraOp, value=false
    ConstantValue49
      value:
        boolean literal ConstantValue49: type=DT_Ext_bNotAvl_resBattIt, value=false
    ConstantValue5
      value:
        boolean literal ConstantValue5: type=DT_CoTqRStrt_bEngStrtSuc, value=false
    ConstantValue51
      value:
        integer literal ConstantValue51: type=DT_Ext_tOilMes, value=0
    ConstantValue53
      value:
        integer literal ConstantValue53: type=DT_RvAltMgt_tRvAltStatEstim, value=-15
    ConstantValue55
      value:
        integer literal ConstantValue55: type=DT_CoPtASE_stPwt, value=1
    ConstantValue57
      value:
        integer literal ConstantValue57: type=DT_CoPTStNew_stEng, value=1
    ConstantValue59
      value:
        boolean literal ConstantValue59: type=DT_CoPtUH_bRStrtMchAuth, value=false
    ConstantValue61
      value:
        boolean literal ConstantValue61: type=DT_CoPtUH_bRStrtReqAvl, value=false
    ConstantValue63
      value:
        integer literal ConstantValue63: type=DT_CoPtUH_stMaxRStrtReq, value=0
    ConstantValue65
      value:
        integer literal ConstantValue65: type=DT_CoPtUH_stPwt, value=1
    ConstantValue67
      value:
        integer literal ConstantValue67: type=DT_Ext_stGBxCf, value=0
    ConstantValue69
      value:
        boolean literal ConstantValue69: type=DT_CoPtUH_bBltStopAuth, value=false
    ConstantValue7
      value:
        boolean literal ConstantValue7: type=DT_ECU_bWkuMain, value=false
    ConstantValue71
      value:
        integer literal ConstantValue71: type=DT_CoPt_spdVehGearRatCord, value=0
    ConstantValue73
      value:
        boolean literal ConstantValue73: type=DT_PARM_bEngRstrtAutnAvl, value=false
    ConstantValue75
      value:
        boolean literal ConstantValue75: type=DT_CoPtUH_bFbSpcFactSTTReq1, value=false
    ConstantValue77
      value:
        integer literal ConstantValue77: type=DT_CoPtUH_stSTTLightAcv, value=0
    ConstantValue79
      value:
        integer literal ConstantValue79: type=DT_Ext_stTraTypCf, value=0
    ConstantValue81
      value:
        integer literal ConstantValue81: type=DT_CoReqCha_stEngRStrtInh, value=0
    ConstantValue83
      value:
        boolean literal ConstantValue83: type=DT_CoPtUH_bInhHiSpdAltRstrtReq, value=false
    ConstantValue85
      value:
        boolean literal ConstantValue85: type=DT_CoPtUH_bCompTqRStrt, value=false
    ConstantValue87
      value:
        integer literal ConstantValue87: type=DT_Ext_tAir, value=20
    ConstantValue89
      value:
        boolean literal ConstantValue89: type=DT_CoPtUH_bEngRstrtClsCluCdn, value=false
    ConstantValue9
      value:
        boolean literal ConstantValue9: type=DT_EngReqH_bEngRStrtAutnAvl, value=false
    ConstantValue91
      value:
        boolean literal ConstantValue91: type=DT_CoPtUH_bCompTqRStrt, value=false
    ConstantValue93
      value:
        boolean literal ConstantValue93: type=DT_CoPtUH_bDrvTraOp, value=false
    ConstantValue95
      value:
        boolean literal ConstantValue95: type=DT_CoPtUH_bFbSpcFactSTTReq1, value=false
    ConstantValue97
      value:
        boolean literal ConstantValue97: type=DT_CoPtUH_bFbSpcFactSTTReq2, value=false
    ConstantValue99
      value:
        integer literal ConstantValue99: type=DT_CoPtUH_stSTTLightAcv, value=0
    CoOptmEl_stElEProv_in
      value:
        integer literal CoOptmEl_stElEProv_in: type=DT_CoOptmEl_stElEProv, value=1
    CoOptmEl_tqAlt_in
      value:
        integer literal CoOptmEl_tqAlt_in: type=DT_CoOptmEl_tqAlt, value=0
    CoPt_bInhEngStopProtManClu_Cst
      value:
        boolean literal CoPt_bInhEngStopProtManClu_Cst: type=DT_CoPt_bInhEngStopProtManClu, value=false
    CoPtUH_bAcvGSINeut_Cst
      value:
        boolean literal CoPtUH_bAcvGSINeut_Cst: type=DT_CoPtUH_bAcvGSINeut, value=false
    CoPtUH_bAltInh_out
      value:
        boolean literal CoPtUH_bAltInh_out: type=DT_CoPtUH_bAltInh, value=true
    CoPtUH_bAltPrepRStrtReq_out
      value:
        boolean literal CoPtUH_bAltPrepRStrtReq_out: type=DT_CoPtUH_bAltPrepRStrtReq, value=false
    CoPtUH_bAltRPosnEngReq_out
      value:
        boolean literal CoPtUH_bAltRPosnEngReq_out: type=DT_CoPtUH_bAltRPosnEngReq, value=false
    CoPtUH_bAltRStrtReq_in
      value:
        boolean literal CoPtUH_bAltRStrtReq_in: type=DT_CoPtUH_bAltRStrtReq, value=false
    CoPtUH_bAltRStrtReq_out
      value:
        boolean literal CoPtUH_bAltRStrtReq_out: type=DT_CoPtUH_bAltRStrtReq, value=false
    CoPtUH_bAltStallReq_out
      value:
        boolean literal CoPtUH_bAltStallReq_out: type=DT_CoPtUH_bAltStallReq, value=false
    CoPtUH_bCdnInhRStrt_out
      value:
        boolean literal CoPtUH_bCdnInhRStrt_out: type=DT_CoPtUH_bCdnInhRStrt, value=false
    CoPtUH_bCtlDmprAuth_out
      value:
        boolean literal CoPtUH_bCtlDmprAuth_out: type=DT_CoPtUH_bCtlDmprAuth, value=false
    CoPtUH_bCutCaseAutRStrt_out
      value:
        boolean literal CoPtUH_bCutCaseAutRStrt_out: type=DT_CoPtUH_bCutCaseAutRStrt, value=false
    CoPtUH_bCutCaseClsTra_out
      value:
        boolean literal CoPtUH_bCutCaseClsTra_out: type=DT_CoPtUH_bCutCaseClsTra, value=false
    CoPtUH_bCutCaseDgoBlt_out
      value:
        boolean literal CoPtUH_bCutCaseDgoBlt_out: type=DT_CoPtUH_bCutCaseDgoBlt, value=false
    CoPtUH_bCutCaseElMecRStrtReq_out
      value:
        boolean literal CoPtUH_bCutCaseElMecRStrtReq_out: type=DT_CoPtUH_bCutCaseElMecRStrtReq, value=false
    CoPtUH_bCutCaseLongGc_out
      value:
        boolean literal CoPtUH_bCutCaseLongGc_out: type=DT_CoPtUH_bCutCaseLongGc, value=false
    CoPtUH_bCutCaseNotRStrtAuth_out
      value:
        boolean literal CoPtUH_bCutCaseNotRStrtAuth_out: type=DT_CoPtUH_bCutCaseNotRStrtAuth, value=false
    CoPtUH_bCutCaseRCfTyp3_out
      value:
        boolean literal CoPtUH_bCutCaseRCfTyp3_out: type=DT_CoPtUH_bCutCaseRCfTyp3, value=false
    CoPtUH_bCutCaseRStrtReqForc_out
      value:
        boolean literal CoPtUH_bCutCaseRStrtReqForc_out: type=DT_CoPtUH_bCutCaseRStrtReqForc, value=false
    CoPtUH_bCutCaseSpdMax_out
      value:
        boolean literal CoPtUH_bCutCaseSpdMax_out: type=DT_CoPtUH_bCutCaseSpdMax, value=false
    CoPtUH_bCutCaseVehRStrtReq_out
      value:
        boolean literal CoPtUH_bCutCaseVehRStrtReq_out: type=DT_CoPtUH_bCutCaseVehRStrtReq, value=false
    CoPtUH_bEngCutOffReq_in
      value:
        boolean literal CoPtUH_bEngCutOffReq_in: type=DT_CoPtUH_bEngCutOffReq, value=false
    CoPtUH_bEngCutOffReq_out
      value:
        boolean literal CoPtUH_bEngCutOffReq_out: type=DT_CoPtUH_bEngCutOffReq, value=false
    CoPtUH_bEngRStrtReq_out
      value:
        boolean literal CoPtUH_bEngRStrtReq_out: type=DT_CoPtUH_bEngRStrtReq, value=false
    CoPtUH_bEngStopReq_out
      value:
        boolean literal CoPtUH_bEngStopReq_out: type=DT_CoPtUH_bEngStopReq, value=false
    CoPtUH_bInfoAcvCluPed_out
      value:
        boolean literal CoPtUH_bInfoAcvCluPed_out: type=DT_CoPtUH_bInfoAcvCluPed, value=false
    CoPtUH_bInfoRdy_out
      value:
        boolean literal CoPtUH_bInfoRdy_out: type=DT_CoPtUH_bInfoRdy, value=false
    CoPtUH_bLatchDrvCyc_out
      value:
        boolean literal CoPtUH_bLatchDrvCyc_out: type=DT_CoPtUH_bLatchDrvCyc, value=false
    CoPtUH_bOpDrvTraReq_in
      value:
        boolean literal CoPtUH_bOpDrvTraReq_in: type=DT_CoPtUH_bOpDrvTraReq, value=false
    CoPtUH_bOpDrvTraReq_out
      value:
        boolean literal CoPtUH_bOpDrvTraReq_out: type=DT_CoPtUH_bOpDrvTraReq, value=false
    CoPtUH_bRecNotStop_out
      value:
        boolean literal CoPtUH_bRecNotStop_out: type=DT_CoPtUH_bRecNotStop, value=false
    CoPtUH_bRStrtAnt_out
      value:
        boolean literal CoPtUH_bRStrtAnt_out: type=DT_CoPtUH_bRStrtAnt, value=false
    CoPtUH_bRstrtCritAuth_in
      value:
        boolean literal CoPtUH_bRstrtCritAuth_in: type=DT_CoPtUH_bRstrtCritAuth, value=false
    CoPtUH_bRstrtCritAuth_out
      value:
        boolean literal CoPtUH_bRstrtCritAuth_out: type=DT_CoPtUH_bRstrtCritAuth, value=false
    CoPtUH_bRStrtTypAT_out
      value:
        boolean literal CoPtUH_bRStrtTypAT_out: type=DT_CoPtUH_bRStrtTypAT, value=false
    CoPtUH_bStopAuthSlop_out
      value:
        boolean literal CoPtUH_bStopAuthSlop_out: type=DT_CoPtUH_bStopAuthSlop, value=false
    CoPtUH_bStPresLo_in
      value:
        boolean literal CoPtUH_bStPresLo_in: type=DT_CoPtUH_bStPresLo, value=false
    CoPtUH_bStPresLo_out
      value:
        boolean literal CoPtUH_bStPresLo_out: type=DT_CoPtUH_bStPresLo, value=false
    CoPtUH_bSTTInh_in
      value:
        boolean literal CoPtUH_bSTTInh_in: type=DT_CoPtUH_bSTTInh, value=false
    CoPtUH_bSTTInh_out
      value:
        boolean literal CoPtUH_bSTTInh_out: type=DT_CoPtUH_bSTTInh, value=false
    CoPtUH_bTestPrvtBltAcv_out
      value:
        boolean literal CoPtUH_bTestPrvtBltAcv_out: type=DT_CoPtUH_bTestPrvtBltAcv, value=false
    CoPtUH_bVSSNwAcvAuth_out
      value:
        boolean literal CoPtUH_bVSSNwAcvAuth_out: type=DT_CoPtUH_bVSSNwAcvAuth, value=false
    CoPtUH_nEngClc_out
      value:
        integer literal CoPtUH_nEngClc_out: type=DT_CoPtUH_nEngClc, value=0
    CoPtUH_noGearTmpBeg_out
      value:
        integer literal CoPtUH_noGearTmpBeg_out: type=DT_CoPtUH_noGearTmpBeg, value=0
    CoPtUH_noGearTmpEnd_out
      value:
        integer literal CoPtUH_noGearTmpEnd_out: type=DT_CoPtUH_noGearTmpEnd, value=0
    CoPtUH_pRelBrkAsi_out
      value:
        integer literal CoPtUH_pRelBrkAsi_out: type=DT_CoPtUH_pRelBrkAsi, value=2
    CoPtUH_rMaxCluGc_out
      value:
        integer literal CoPtUH_rMaxCluGc_out: type=DT_CoPtUH_rMaxCluGc, value=0
    CoPtUH_rMinCluRStrt_out
      value:
        integer literal CoPtUH_rMinCluRStrt_out: type=DT_CoPtUH_rMinCluRStrt, value=0
    CoPtUH_stAftsRStrtSuc_out
      value:
        integer literal CoPtUH_stAftsRStrtSuc_out: type=DT_CoPtUH_stAftsRStrtSuc, value=0
    CoPtUH_stBfBfLstRStrtFail_out
      value:
        integer literal CoPtUH_stBfBfLstRStrtFail_out: type=DT_CoPtUH_stBfBfLstRStrtFail, value=0
    CoPtUH_stBfLstRStrtFailCase_out
      value:
        integer literal CoPtUH_stBfLstRStrtFailCase_out: type=DT_CoPtUH_stBfLstRStrtFailCase, value=0
    CoPtUH_stFbSpcFactRStrtSuc_out
      value:
        integer literal CoPtUH_stFbSpcFactRStrtSuc_out: type=DT_CoPtUH_stFbSpcFactRStrtSuc, value=0
    CoPtUH_stLstRStrtFailCase_out
      value:
        integer literal CoPtUH_stLstRStrtFailCase_out: type=DT_CoPtUH_stLstRStrtFailCase, value=0
    CoPtUH_stTestPosClu_out
      value:
        integer literal CoPtUH_stTestPosClu_out: type=DT_CoPtUH_stTestPosClu, value=0
    CoPtUH_tiNbRstrtFreqLim_out
      value:
        integer literal CoPtUH_tiNbRstrtFreqLim_out: type=DT_CoPtUH_tiNbRstrtFreqLim, value=0
    CoReqAMT_bEngRStrtReq_in
      value:
        boolean literal CoReqAMT_bEngRStrtReq_in: type=DT_CoReqAMT_bEngRStrtReq, value=false
    CoReqAMT_stEngStopAuth_in
      value:
        integer literal CoReqAMT_stEngStopAuth_in: type=DT_CoReqAMT_stEngStopAuth, value=0
    CoReqCha_bEngRStrtReq_in
      value:
        boolean literal CoReqCha_bEngRStrtReq_in: type=DT_CoReqCha_bEngRStrtReq, value=false
    CoReqCha_bHillAsiRdyEngStop_in
      value:
        boolean literal CoReqCha_bHillAsiRdyEngStop_in: type=DT_CoReqCha_bHillAsiRdyEngStop, value=false
    CoReqCha_bUncrtSlopStab_in
      value:
        boolean literal CoReqCha_bUncrtSlopStab_in: type=DT_CoReqCha_bUncrtSlopStab, value=false
    CoReqCha_rSlopStab_in
      value:
        integer literal CoReqCha_rSlopStab_in: type=DT_CoReqCha_rSlopStab, value=-30
    CoReqCha_stEngStopAuth_in
      value:
        integer literal CoReqCha_stEngStopAuth_in: type=DT_CoReqCha_stEngStopAuth, value=0
    CoReqDmpr_bEngRStrtReq_in
      value:
        boolean literal CoReqDmpr_bEngRStrtReq_in: type=DT_CoReqDmpr_bEngRStrtReq, value=false
    CoReqDmpr_stEngStopAuth_in
      value:
        integer literal CoReqDmpr_stEngStopAuth_in: type=DT_CoReqDmpr_stEngStopAuth, value=1
    CoReqRStrt_bAuthSA_in
      value:
        boolean literal CoReqRStrt_bAuthSA_in: type=DT_CoReqRStrt_bAuthSA, value=false
    CoReqRStrt_bAuthSA_out
      value:
        boolean literal CoReqRStrt_bAuthSA_out: type=DT_CoReqRStrt_bAuthSA, value=false
    CoReqRStrt_bEngRStrtReq_in
      value:
        boolean literal CoReqRStrt_bEngRStrtReq_in: type=DT_CoReqRStrt_bEngRStrtReq, value=false
    CoReqRStrt_bEngRStrtReq_out
      value:
        boolean literal CoReqRStrt_bEngRStrtReq_out: type=DT_CoReqRStrt_bEngRStrtReq, value=false
    CoReqRStrt_bEngStopAuth_in
      value:
        boolean literal CoReqRStrt_bEngStopAuth_in: type=DT_CoReqRStrt_bEngStopAuth, value=false
    CoReqRStrt_bEngStopAuth_out
      value:
        boolean literal CoReqRStrt_bEngStopAuth_out: type=DT_CoReqRStrt_bEngStopAuth, value=false
    CoReqRStrt_bNotBlsVehReq_out
      value:
        boolean literal CoReqRStrt_bNotBlsVehReq_out: type=DT_CoReqRStrt_bNotBlsVehReq, value=false
    CoReqRStrt_bRstrtAuth_out
      value:
        boolean literal CoReqRStrt_bRstrtAuth_out: type=DT_CoReqRStrt_bRstrtAuth, value=true
    CoReqRStrt_stRStrtTyp_in
      value:
        integer literal CoReqRStrt_stRStrtTyp_in: type=DT_CoReqRStrt_stRStrtTyp, value=0
    CoReqRStrt_stRStrtTyp_out
      value:
        integer literal CoReqRStrt_stRStrtTyp_out: type=DT_CoReqRStrt_stRStrtTyp, value=0
    CoReqStg_bEngRStrtReq_in
      value:
        boolean literal CoReqStg_bEngRStrtReq_in: type=DT_CoReqStg_bEngRStrtReq, value=false
    CoReqStg_stEngStopAuth_in
      value:
        integer literal CoReqStg_stEngStopAuth_in: type=DT_CoReqStg_stEngStopAuth, value=0
    CoReqVeh_stEngStopAuth_in
      value:
        integer literal CoReqVeh_stEngStopAuth_in: type=DT_CoReqVeh_stEngStopAuth, value=0
    CoRStrt_bRstrtReq_Cst
      value:
        boolean literal CoRStrt_bRstrtReq_Cst: type=DT_CoRStrt_bRstrtReq, value=false
    CoStop_bStopAuthInfoRdy_Cst
      value:
        boolean literal CoStop_bStopAuthInfoRdy_Cst: type=DT_CoStop_bStopAuthInfoRdy, value=false
    CoStop_bStopReq_Cst
      value:
        boolean literal CoStop_bStopReq_Cst: type=DT_CoStop_bStopReq, value=false
    CoStrt_bStrtAuth_in
      value:
        boolean literal CoStrt_bStrtAuth_in: type=DT_CoStrt_bStrtAuth, value=false
    CoSync_bAgEsCfm_in
      value:
        boolean literal CoSync_bAgEsCfm_in: type=DT_CoSync_bAgEsCfm, value=false
    CoSync_bStuckEngStaAcv_in
      value:
        boolean literal CoSync_bStuckEngStaAcv_in: type=DT_CoSync_bStuckEngStaAcv, value=false
    CoTqRStrt_bTraTqAuthRaw_in
      value:
        boolean literal CoTqRStrt_bTraTqAuthRaw_in: type=DT_CoTqRStrt_bTraTqAuthRaw, value=false
    DgoFct_bHealDiagCfLvl1_Cst
      value:
        boolean literal DgoFct_bHealDiagCfLvl1_Cst: type=DT_DgoFct_bHealDiagCfLvl1, value=false
    DgoFct_bSTTOff_Cst
      value:
        boolean literal DgoFct_bSTTOff_Cst: type=DT_DgoFct_bSTTOff, value=false
    DgoFct_stRstrtReq_Cst
      value:
        integer literal DgoFct_stRstrtReq_Cst: type=DT_DgoFct_stRstrtReq, value=0
    EngReqH_bEngRunReq_in
      value:
        boolean literal EngReqH_bEngRunReq_in: type=DT_EngReqH_bEngRunReq, value=false
    EngReqH_stEngStopAuth_in
      value:
        integer literal EngReqH_stEngStopAuth_in: type=DT_EngReqH_stEngStopAuth, value=0
    Ext_bEfcBrkPedPrss_in
      value:
        boolean literal Ext_bEfcBrkPedPrss_in: type=DT_Ext_bEfcBrkPedPrss, value=false
    Ext_bNotAvl_uBattOc_in
      value:
        boolean literal Ext_bNotAvl_uBattOc_in: type=DT_Ext_bNotAvl_uBattOc, value=false
    Ext_bPush_in
      value:
        boolean literal Ext_bPush_in: type=DT_Ext_bPush, value=false
    Ext_bRStrtAuthTra_in
      value:
        boolean literal Ext_bRStrtAuthTra_in: type=DT_Ext_bRStrtAuthTra, value=false
    Ext_dstVehTotMes_in
      value:
        integer literal Ext_dstVehTotMes_in: type=DT_Ext_dstVehTotMes, value=0
    Ext_pAirExtMes_in
      value:
        integer literal Ext_pAirExtMes_in: type=DT_Ext_pAirExtMes, value=500
    Ext_pBrkAsi_in
      value:
        integer literal Ext_pBrkAsi_in: type=DT_Ext_pBrkAsi, value=1000
    Ext_pBrkMCT_in
      value:
        integer literal Ext_pBrkMCT_in: type=DT_Ext_pBrkMCT, value=0
    Ext_posnGBxLev_in
      value:
        integer literal Ext_posnGBxLev_in: type=DT_Ext_posnGBxLev, value=0
    Ext_pRelBrkAsi_in
      value:
        integer literal Ext_pRelBrkAsi_in: type=DT_Ext_pRelBrkAsi, value=2
    Ext_spdVehSecu_in
      value:
        integer literal Ext_spdVehSecu_in: type=DT_Ext_spdVehSecu, value=0
    Ext_tOilGBx_in
      value:
        integer literal Ext_tOilGBx_in: type=DT_Ext_tOilGBx, value=0
    MgtAlt_bIntrAltRstrtReqRaw_Cst
      value:
        boolean literal MgtAlt_bIntrAltRstrtReqRaw_Cst: type=DT_MgtAlt_bIntrAltRstrtReqRaw, value=false
    MgtDrv_bDftHld_Cst
      value:
        boolean literal MgtDrv_bDftHld_Cst: type=DT_MgtDrv_bDftHld, value=false
    MgtDrv_bRiseSpcFacSTTReq1_Cst
      value:
        boolean literal MgtDrv_bRiseSpcFacSTTReq1_Cst: type=DT_MgtDrv_bRiseSpcFacSTTReq1, value=false
    MgtEng_bLgRstrt_Cst
      value:
        boolean literal MgtEng_bLgRstrt_Cst: type=DT_MgtEng_bLgRstrt, value=false
    MonDrv_bGSIStopAuth_Cst
      value:
        boolean literal MonDrv_bGSIStopAuth_Cst: type=DT_MonDrv_bGSIStopAuth, value=false
    MonDrv_bPrepInfoRdy_Cst
      value:
        boolean literal MonDrv_bPrepInfoRdy_Cst: type=DT_MonDrv_bPrepInfoRdy, value=false
    MonDrv_bPrepRstrtReq_Cst
      value:
        boolean literal MonDrv_bPrepRstrtReq_Cst: type=DT_MonDrv_bPrepRstrtReq, value=false
    MonDrv_bReqOpTraAT_Cst
      value:
        boolean literal MonDrv_bReqOpTraAT_Cst: type=DT_MonDrv_bReqOpTraAT, value=false
    MonDrv_bRstrtAntCncl_Cst
      value:
        boolean literal MonDrv_bRstrtAntCncl_Cst: type=DT_MonDrv_bRstrtAntCncl, value=false
    MonDrv_bRstrtAntReq_Cst
      value:
        boolean literal MonDrv_bRstrtAntReq_Cst: type=DT_MonDrv_bRstrtAntReq, value=false
    MonDrv_bRstrtCritAuthAnt_Cst
      value:
        boolean literal MonDrv_bRstrtCritAuthAnt_Cst: type=DT_MonDrv_bRstrtCritAuthAnt, value=false
    MonDrv_bRstrtReq_Cst
      value:
        boolean literal MonDrv_bRstrtReq_Cst: type=DT_MonDrv_bRstrtReq, value=false
    MonDrv_bStopAuth_Cst
      value:
        boolean literal MonDrv_bStopAuth_Cst: type=DT_MonDrv_bStopAuth, value=false
    MonDrv_bStopAuthRaw_Cst
      value:
        boolean literal MonDrv_bStopAuthRaw_Cst: type=DT_MonDrv_bStopAuthRaw, value=false
    MonDrv_bStopCdnChg_Cst
      value:
        boolean literal MonDrv_bStopCdnChg_Cst: type=DT_MonDrv_bStopCdnChg, value=false
    MonDrv_stRstrtReq_Cst
      value:
        integer literal MonDrv_stRstrtReq_Cst: type=DT_MonDrv_stRstrtReq, value=0
    MonEE_bStopAuth_Cst
      value:
        boolean literal MonEE_bStopAuth_Cst: type=DT_MonEE_bStopAuth, value=false
    MonEE_stRstrtReq_Cst
      value:
        integer literal MonEE_stRstrtReq_Cst: type=DT_MonEE_stRstrtReq, value=0
    MonEng_bStopAuth_Cst
      value:
        boolean literal MonEng_bStopAuth_Cst: type=DT_MonEng_bStopAuth, value=false
    MonEng_bStopEngRdy_Cst
      value:
        boolean literal MonEng_bStopEngRdy_Cst: type=DT_MonEng_bStopEngRdy, value=false
    MonEng_stRstrtReq_Cst
      value:
        integer literal MonEng_stRstrtReq_Cst: type=DT_MonEng_stRstrtReq, value=0
    MonGB_bCutCaseLgGc_Cst
      value:
        boolean literal MonGB_bCutCaseLgGc_Cst: type=DT_MonGB_bCutCaseLgGc, value=false
    MonGB_bMAPRstrtAuth_Cst
      value:
        boolean literal MonGB_bMAPRstrtAuth_Cst: type=DT_MonGB_bMAPRstrtAuth, value=false
    MonGB_bRstrtAuth_Cst
      value:
        boolean literal MonGB_bRstrtAuth_Cst: type=DT_MonGB_bRstrtAuth, value=false
    MonGB_bRstrtTypATReq_Cst
      value:
        boolean literal MonGB_bRstrtTypATReq_Cst: type=DT_MonGB_bRstrtTypATReq, value=false
    MonGB_bStopAuth_Cst
      value:
        boolean literal MonGB_bStopAuth_Cst: type=DT_MonGB_bStopAuth, value=false
    MonGB_stRstrtReq_Cst
      value:
        integer literal MonGB_stRstrtReq_Cst: type=DT_MonGB_stRstrtReq, value=0
    MonVeh_bDeacHillAsi_Cst
      value:
        boolean literal MonVeh_bDeacHillAsi_Cst: type=DT_MonVeh_bDeacHillAsi, value=false
    MonVeh_bHiSpdRstrtAuth_Cst
      value:
        boolean literal MonVeh_bHiSpdRstrtAuth_Cst: type=DT_MonVeh_bHiSpdRstrtAuth, value=false
    MonVeh_bInfoHillAsiDrvRstrt_Cst
      value:
        boolean literal MonVeh_bInfoHillAsiDrvRstrt_Cst: type=DT_MonVeh_bInfoHillAsiDrvRstrt, value=false
    MonVeh_bOpDrvTraAuth_Cst
      value:
        boolean literal MonVeh_bOpDrvTraAuth_Cst: type=DT_MonVeh_bOpDrvTraAuth, value=false
    MonVeh_bPresPtlRstrtReqForc_Cst
      value:
        boolean literal MonVeh_bPresPtlRstrtReqForc_Cst: type=DT_MonVeh_bPresPtlRstrtReqForc, value=false
    MonVeh_bPtlVehRstrtReqForc_Cst
      value:
        boolean literal MonVeh_bPtlVehRstrtReqForc_Cst: type=DT_MonVeh_bPtlVehRstrtReqForc, value=false
    MonVeh_bRstrtAuth_Cst
      value:
        boolean literal MonVeh_bRstrtAuth_Cst: type=DT_MonVeh_bRstrtAuth, value=false
    MonVeh_bRstrtAuthMch_Cst
      value:
        boolean literal MonVeh_bRstrtAuthMch_Cst: type=DT_MonVeh_bRstrtAuthMch, value=false
    MonVeh_bStopAuth_Cst
      value:
        boolean literal MonVeh_bStopAuth_Cst: type=DT_MonVeh_bStopAuth, value=false
    MonVeh_stRstrtReq_Cst
      value:
        integer literal MonVeh_stRstrtReq_Cst: type=DT_MonVeh_stRstrtReq, value=0
    PredEs_agEs_in
      value:
        integer literal PredEs_agEs_in: type=DT_PredEs_agEs, value=0
    PredEs_agUncrtEs_in
      value:
        integer literal PredEs_agUncrtEs_in: type=DT_PredEs_agUncrtEs, value=90
    PredEs_nFast_in
      value:
        integer literal PredEs_nFast_in: type=DT_PredEs_nFast, value=0
    PredRstrt_noTDC_in
      value:
        integer literal PredRstrt_noTDC_in: type=DT_PredRstrt_noTDC, value=3
    PredRstrt_tiMax2TDC_in
      value:
        integer literal PredRstrt_tiMax2TDC_in: type=DT_PredRstrt_tiMax2TDC, value=0
    RvAltMgt_nRvAltMes_in
      value:
        integer literal RvAltMgt_nRvAltMes_in: type=DT_RvAltMgt_nRvAltMes, value=0
    RvAltMgt_nRvAltMv_in
      value:
        integer literal RvAltMgt_nRvAltMv_in: type=DT_RvAltMgt_nRvAltMv, value=0
    RvAltMgt_tqRstrtMaxEstim_in
      value:
        integer literal RvAltMgt_tqRstrtMaxEstim_in: type=DT_RvAltMgt_tqRstrtMaxEstim, value=0
    RvAltMgt_tqRvAltGenModMv_in
      value:
        integer literal RvAltMgt_tqRvAltGenModMv_in: type=DT_RvAltMgt_tqRvAltGenModMv, value=0
    Sfty_bInhEngStopSTTReq_in
      value:
        boolean literal Sfty_bInhEngStopSTTReq_in: type=DT_Sfty_bInhEngStopSTTReq, value=false
    Sync_agEng_in
      value:
        integer literal Sync_agEng_in: type=DT_Sync_agEng, value=0
    TqLimUH_bAcvUnBlsEng_Cst
      value:
        boolean literal TqLimUH_bAcvUnBlsEng_Cst: type=DT_TqLimUH_bAcvUnBlsEng, value=false
    TqLimUH_stDrivTyp_in
      value:
        integer literal TqLimUH_stDrivTyp_in: type=DT_TqLimUH_stDrivTyp, value=0
    Tra_noEgdGear_in
      value:
        integer literal Tra_noEgdGear_in: type=DT_Tra_noEgdGear, value=0
    Tra_noTarGear_in
      value:
        integer literal Tra_noTarGear_in: type=DT_Tra_noTarGear, value=0
    Tra_stGBxMod_in
      value:
        integer literal Tra_stGBxMod_in: type=DT_Tra_stGBxMod, value=0
    Veh_stDrvAvl_in
      value:
        integer literal Veh_stDrvAvl_in: type=DT_Veh_stDrvAvl, value=0
  internal behavior IB_CoStopStart: component=COSTOPSTART
    mode switch event EV_CoStopStart_025_MSE: start-on-event=RE_CoStopStart_025_MSE, activation=ENTRY, mode=R_EcuM_CurrentMode.currentMode.RUN
    mode switch event EV_CoStopStart_027_MSE: start-on-event=RE_CoStopStart_027_MSE, activation=ENTRY, mode=R_EcuM_CurrentMode.currentMode.RUN
    timing event EV_CoStopStart_016_TEV: mode-dependency=dependent-on-mode=[R_UCE_stWkuMainRelSt.RCD_stWkuMainRelSt.PreMainWakeUp, R_UCE_stWkuMainRelSt.RCD_stWkuMainRelSt.PostMainWakeUp, R_UCE_stWkuMainRelSt.RCD_stWkuMainRelSt.Invalid], start-on-event=RE_CoStopStart_016_TEV, period=0.01
    mode switch event EV_CoStopStart_007_MSE: start-on-event=RE_CoStopStart_007_MSE, activation=ENTRY, mode=R_EcuM_CurrentMode.currentMode.RUN
    mode switch event EV_CoStopStart_009_MSE: start-on-event=RE_CoStopStart_009_MSE, activation=ENTRY, mode=R_EcuM_CurrentMode.currentMode.RUN
    operation invoked event EV_CoStopStart_AftsNvramWrite_1: start-on-event=RE_CoStopStart_AftsNvramWrite_1, operation=P_CoStopStart_AftsNvramWrite_1.CoStopStart_AftsNvramWrite_1
    timing event EV_CoStopStart_032_TEV: mode-dependency=dependent-on-mode=[R_UCE_stWkuMainRelSt.RCD_stWkuMainRelSt.PreMainWakeUp, R_UCE_stWkuMainRelSt.RCD_stWkuMainRelSt.PostMainWakeUp, R_UCE_stWkuMainRelSt.RCD_stWkuMainRelSt.Invalid], start-on-event=RE_CoStopStart_032_TEV, period=0.01
    timing event EV_CoStopStart_010_TEV: mode-dependency=dependent-on-mode=[R_UCE_stWkuMainRelSt.RCD_stWkuMainRelSt.PreMainWakeUp, R_UCE_stWkuMainRelSt.RCD_stWkuMainRelSt.PostMainWakeUp, R_UCE_stWkuMainRelSt.RCD_stWkuMainRelSt.Invalid], start-on-event=RE_CoStopStart_010_TEV, period=0.01
    operation invoked event EV_CoStopStart_AftsNvramReset_1: start-on-event=RE_CoStopStart_AftsNvramReset_1, operation=P_CoStopStart_AftsNvramReset_1.CoStopStart_AftsNvramReset_1
    timing event EV_CoStopStart_004_TEV: mode-dependency=dependent-on-mode=[R_UCE_stWkuMainRelSt.RCD_stWkuMainRelSt.PreMainWakeUp, R_UCE_stWkuMainRelSt.RCD_stWkuMainRelSt.PostMainWakeUp, R_UCE_stWkuMainRelSt.RCD_stWkuMainRelSt.Invalid], start-on-event=RE_CoStopStart_004_TEV, period=0.01
    timing event EV_CoStopStart_020_TEV: mode-dependency=dependent-on-mode=[R_UCE_stWkuMainRelSt.RCD_stWkuMainRelSt.PreMainWakeUp, R_UCE_stWkuMainRelSt.RCD_stWkuMainRelSt.PostMainWakeUp, R_UCE_stWkuMainRelSt.RCD_stWkuMainRelSt.Invalid], start-on-event=RE_CoStopStart_020_TEV, period=0.01
    mode switch event EV_CoStopStart_017_MSE: start-on-event=RE_CoStopStart_017_MSE, activation=ENTRY, mode=R_EcuM_CurrentMode.currentMode.RUN
    mode switch event EV_CoStopStart_021_MSE: start-on-event=RE_CoStopStart_021_MSE, activation=ENTRY, mode=R_EcuM_CurrentMode.currentMode.RUN
    timing event EV_CoStopStart_008_TEV: mode-dependency=dependent-on-mode=[R_UCE_stWkuMainRelSt.RCD_stWkuMainRelSt.PreMainWakeUp, R_UCE_stWkuMainRelSt.RCD_stWkuMainRelSt.PostMainWakeUp, R_UCE_stWkuMainRelSt.RCD_stWkuMainRelSt.Invalid], start-on-event=RE_CoStopStart_008_TEV, period=0.01
    mode switch event EV_CoStopStart_013_MSE: start-on-event=RE_CoStopStart_013_MSE, activation=ENTRY, mode=R_EcuM_CurrentMode.currentMode.RUN
    operation invoked event EV_CoStopStart_AftsNvramRead_1: start-on-event=RE_CoStopStart_AftsNvramRead_1, operation=P_CoStopStart_AftsNvramRead_1.CoStopStart_AftsNvramRead_1
    mode switch event EV_CoStopStart_019_MSE: start-on-event=RE_CoStopStart_019_MSE, activation=ENTRY, mode=R_EcuM_CurrentMode.currentMode.RUN
    6 x timing event, all with mode-dependency=dependent-on-mode=[R_UCE_stWkuMainRelSt.RCD_stWkuMainRelSt.PreMainWakeUp, R_UCE_stWkuMainRelSt.RCD_stWkuMainRelSt.PostMainWakeUp, R_UCE_stWkuMainRelSt.RCD_stWkuMainRelSt.Invalid], period=0.01:
      EV_CoStopStart_014_TEV: start-on-event=RE_CoStopStart_014_TEV
      EV_CoStopStart_030_TEV: start-on-event=RE_CoStopStart_030_TEV
      EV_CoStopStart_022_TEV: start-on-event=RE_CoStopStart_022_TEV
      EV_CoStopStart_026_TEV: start-on-event=RE_CoStopStart_026_TEV
      EV_CoStopStart_012_TEV: start-on-event=RE_CoStopStart_012_TEV
      EV_CoStopStart_024_TEV: start-on-event=RE_CoStopStart_024_TEV
    5 x mode switch event, all with activation=ENTRY, mode=R_EcuM_CurrentMode.currentMode.RUN:
      EV_CoStopStart_015_MSE: start-on-event=RE_CoStopStart_015_MSE
      EV_CoStopStart_023_MSE: start-on-event=RE_CoStopStart_023_MSE
      EV_CoStopStart_031_MSE: start-on-event=RE_CoStopStart_031_MSE
      EV_CoStopStart_011_MSE: start-on-event=RE_CoStopStart_011_MSE
      EV_CoStopStart_029_MSE: start-on-event=RE_CoStopStart_029_MSE
    timing event EV_CoStopStart_028_TEV: mode-dependency=dependent-on-mode=[R_UCE_stWkuMainRelSt.RCD_stWkuMainRelSt.PreMainWakeUp, R_UCE_stWkuMainRelSt.RCD_stWkuMainRelSt.PostMainWakeUp, R_UCE_stWkuMainRelSt.RCD_stWkuMainRelSt.Invalid], start-on-event=RE_CoStopStart_028_TEV, period=0.01
    timing event EV_CoStopStart_018_TEV: mode-dependency=dependent-on-mode=[R_UCE_stWkuMainRelSt.RCD_stWkuMainRelSt.PreMainWakeUp, R_UCE_stWkuMainRelSt.RCD_stWkuMainRelSt.PostMainWakeUp, R_UCE_stWkuMainRelSt.RCD_stWkuMainRelSt.Invalid], start-on-event=RE_CoStopStart_018_TEV, period=0.01
    mode switch event EV_CoStopStart_003_MSE: start-on-event=RE_CoStopStart_003_MSE, activation=ENTRY, mode=R_EcuM_CurrentMode.currentMode.RUN
    47 x inter runnable variable, all with sw-calibration-access=READ-WRITE, communication-approach=EXPLICIT:
      MonDrv_bStopCdnChg: type=DT_MonDrv_bStopCdnChg, init-value=MonDrv_bStopCdnChg_Cst
      MonVeh_bHiSpdRstrtAuth: type=DT_MonVeh_bHiSpdRstrtAuth, init-value=MonVeh_bHiSpdRstrtAuth_Cst
      MonDrv_bRstrtReq: type=DT_MonDrv_bRstrtReq, init-value=MonDrv_bRstrtReq_Cst
      CoStop_bStopReq: type=DT_CoStop_bStopReq, init-value=CoStop_bStopReq_Cst
      MonDrv_bReqOpTraAT: type=DT_MonDrv_bReqOpTraAT, init-value=MonDrv_bReqOpTraAT_Cst
      DgoFct_stRstrtReq: type=DT_DgoFct_stRstrtReq, init-value=DgoFct_stRstrtReq_Cst
      MonGB_bMAPRstrtAuth: type=DT_MonGB_bMAPRstrtAuth, init-value=MonGB_bMAPRstrtAuth_Cst
      MonDrv_bStopAuth: type=DT_MonDrv_bStopAuth, init-value=MonDrv_bStopAuth_Cst
      DgoFct_bSTTOff: type=DT_DgoFct_bSTTOff, init-value=DgoFct_bSTTOff_Cst
      MonEng_stRstrtReq: type=DT_MonEng_stRstrtReq, init-value=MonEng_stRstrtReq_Cst
      DgoFct_bHealDiagCfLvl1: type=DT_DgoFct_bHealDiagCfLvl1, init-value=DgoFct_bHealDiagCfLvl1_Cst
      MonDrv_stRstrtReq: type=DT_MonDrv_stRstrtReq, init-value=MonDrv_stRstrtReq_Cst
      MonGB_stRstrtReq: type=DT_MonGB_stRstrtReq, init-value=MonGB_stRstrtReq_Cst
      MonVeh_bOpDrvTraAuth: type=DT_MonVeh_bOpDrvTraAuth, init-value=MonVeh_bOpDrvTraAuth_Cst
      CoCut_ctForcRstrtFail: type=DT_CoCut_ctForcRstrtFail, init-value=CoCut_ctForcRstrtFail_Cst
      MonVeh_bDeacHillAsi: type=DT_MonVeh_bDeacHillAsi, init-value=MonVeh_bDeacHillAsi_Cst
      CoCut_ctRstrtFail: type=DT_CoCut_ctRstrtFail, init-value=CoCut_ctRstrtFail_Cst
      MgtDrv_bDftHld: type=DT_MgtDrv_bDftHld, init-value=MgtDrv_bDftHld_Cst
      MonVeh_bRstrtAuth: type=DT_MonVeh_bRstrtAuth, init-value=MonVeh_bRstrtAuth_Cst
      MonEE_stRstrtReq: type=DT_MonEE_stRstrtReq, init-value=MonEE_stRstrtReq_Cst
      MgtEng_bLgRstrt: type=DT_MgtEng_bLgRstrt, init-value=MgtEng_bLgRstrt_Cst
      MonGB_bRstrtTypATReq: type=DT_MonGB_bRstrtTypATReq, init-value=MonGB_bRstrtTypATReq_Cst
      MonDrv_bPrepInfoRdy: type=DT_MonDrv_bPrepInfoRdy, init-value=MonDrv_bPrepInfoRdy_Cst
      MonGB_bStopAuth: type=DT_MonGB_bStopAuth, init-value=MonGB_bStopAuth_Cst
      MonDrv_bGSIStopAuth: type=DT_MonDrv_bGSIStopAuth, init-value=MonDrv_bGSIStopAuth_Cst
      MonVeh_bPresPtlRstrtReqForc: type=DT_MonVeh_bPresPtlRstrtReqForc, init-value=MonVeh_bPresPtlRstrtReqForc_Cst
      MonGB_bCutCaseLgGc: type=DT_MonGB_bCutCaseLgGc, init-value=MonGB_bCutCaseLgGc_Cst
      MonEng_bStopAuth: type=DT_MonEng_bStopAuth, init-value=MonEng_bStopAuth_Cst
      CoCut_bElMecIntrRstrt: type=DT_CoCut_bElMecIntrRstrt, init-value=CoCut_bElMecIntrRstrt_Cst
      MonEE_bStopAuth: type=DT_MonEE_bStopAuth, init-value=MonEE_bStopAuth_Cst
      CoCut_bRstrtFail: type=DT_CoCut_bRstrtFail, init-value=CoCut_bRstrtFail_Cst
      MonDrv_bRstrtAntReq: type=DT_MonDrv_bRstrtAntReq, init-value=MonDrv_bRstrtAntReq_Cst
      MonDrv_bStopAuthRaw: type=DT_MonDrv_bStopAuthRaw, init-value=MonDrv_bStopAuthRaw_Cst
      MonDrv_bRstrtCritAuthAnt: type=DT_MonDrv_bRstrtCritAuthAnt, init-value=MonDrv_bRstrtCritAuthAnt_Cst
      CoStop_bStopAuthInfoRdy: type=DT_CoStop_bStopAuthInfoRdy, init-value=CoStop_bStopAuthInfoRdy_Cst
      CoRStrt_bRstrtReq: type=DT_CoRStrt_bRstrtReq, init-value=CoRStrt_bRstrtReq_Cst
      MonGB_bRstrtAuth: type=DT_MonGB_bRstrtAuth, init-value=MonGB_bRstrtAuth_Cst
      MonDrv_bPrepRstrtReq: type=DT_MonDrv_bPrepRstrtReq, init-value=MonDrv_bPrepRstrtReq_Cst
      MonEng_bStopEngRdy: type=DT_MonEng_bStopEngRdy, init-value=MonEng_bStopEngRdy_Cst
      MonDrv_bRstrtAntCncl: type=DT_MonDrv_bRstrtAntCncl, init-value=MonDrv_bRstrtAntCncl_Cst
      MonVeh_bStopAuth: type=DT_MonVeh_bStopAuth, init-value=MonVeh_bStopAuth_Cst
      MonVeh_bRstrtAuthMch: type=DT_MonVeh_bRstrtAuthMch, init-value=MonVeh_bRstrtAuthMch_Cst
      MonVeh_stRstrtReq: type=DT_MonVeh_stRstrtReq, init-value=MonVeh_stRstrtReq_Cst
      MgtAlt_bIntrAltRstrtReqRaw: type=DT_MgtAlt_bIntrAltRstrtReqRaw, init-value=MgtAlt_bIntrAltRstrtReqRaw_Cst
      MgtDrv_bRiseSpcFacSTTReq1: type=DT_MgtDrv_bRiseSpcFacSTTReq1, init-value=MgtDrv_bRiseSpcFacSTTReq1_Cst
      MonVeh_bPtlVehRstrtReqForc: type=DT_MonVeh_bPtlVehRstrtReqForc, init-value=MonVeh_bPtlVehRstrtReqForc_Cst
      MonVeh_bInfoHillAsiDrvRstrt: type=DT_MonVeh_bInfoHillAsiDrvRstrt, init-value=MonVeh_bInfoHillAsiDrvRstrt_Cst
    31 x runnable:
      RE_CoStopStart_AftsNvramReset_1
      RE_CoStopStart_023_MSE: written-variable=[MonDrv_bStopAuthRaw, MonDrv_bPrepInfoRdy, MonDrv_stRstrtReq, MonDrv_bReqOpTraAT, MonDrv_bRstrtCritAuthAnt, MonDrv_bRstrtReq, MonDrv_bRstrtAntReq, MonDrv_bStopCdnChg, MonDrv_bStopAuth, MonDrv_bRstrtAntCncl, MonDrv_bGSIStopAuth, MonDrv_bPrepRstrtReq]
        data send point ds_CoPtUH_bRecNotStop: data-element=P_CoPtUH_bRecNotStop.CoPtUH_bRecNotStop
      RE_CoStopStart_029_MSE: written-variable=[MonGB_bStopAuth, MonGB_bRstrtAuth, MonGB_bMAPRstrtAuth, MonGB_stRstrtReq, MonGB_bRstrtTypATReq, MonGB_bCutCaseLgGc]
        data send point ds_CoPtUH_bDrvTraOp: data-element=P_CoPtUH_bDrvTraOp.CoPtUH_bDrvTraOp
        data send point ds_CoPtUH_bRStrtMchAuth: data-element=P_CoPtUH_bRStrtMchAuth.CoPtUH_bRStrtMchAuth
      RE_CoStopStart_019_MSE: written-variable=[MgtDrv_bRiseSpcFacSTTReq1, MgtDrv_bDftHld]
        7 x data send point:
          ds_CoPtUH_stSTTLightAcv: data-element=P_CoPtUH_stSTTLightAcv.CoPtUH_stSTTLightAcv
          ds_CoPtUH_bInfoRdy: data-element=P_CoPtUH_bInfoRdy.CoPtUH_bInfoRdy
          dsp_CoPtUH_bAcvGSINeut: data-element=P_CoPtUH_bAcvGSINeut.CoPtUH_bAcvGSINeut
          ds_CoPtUH_bFbSpcFactSTTReq1: data-element=P_CoPtUH_bFbSpcFactSTTReq1.CoPtUH_bFbSpcFactSTTReq1
          ds_CoPtUH_bSTTInh: data-element=P_CoPtUH_bSTTInh.CoPtUH_bSTTInh
          ds_CoPtUH_bFbSpcFactSTTReq2: data-element=P_CoPtUH_bFbSpcFactSTTReq2.CoPtUH_bFbSpcFactSTTReq2
          ds_CoPtUH_bInfoAcvCluPed: data-element=P_CoPtUH_bInfoAcvCluPed.CoPtUH_bInfoAcvCluPed
      RE_CoStopStart_020_TEV: read-variable=[CoStop_bStopAuthInfoRdy, CoCut_ctRstrtFail, CoCut_ctForcRstrtFail, MonDrv_bStopAuthRaw, MonDrv_bStopCdnChg, MonDrv_bRstrtReq, MonDrv_bGSIStopAuth, MonDrv_bPrepInfoRdy, MonGB_bRstrtAuth, DgoFct_bSTTOff, MonEng_bStopEngRdy], written-variable=[MgtDrv_bRiseSpcFacSTTReq1, MgtDrv_bDftHld]
        11 x data receive point:
          dr_Afts_stSpcFactSTTReq: data-element=R_Afts_stSpcFactSTTReq.Afts_stSpcFactSTTReq
          dr_CoPtASE_stPwt: data-element=R_CoPtASE_stPwt.CoPtASE_stPwt
          dr_CoPTStNew_stEng: data-element=R_CoPTStNew_stEng.CoPTStNew_stEng
          dr_Sfty_bInhEngStopSTTReq: data-element=R_Sfty_bInhEngStopSTTReq.Sfty_bInhEngStopSTTReq
          dr_Ext_dstVehTotMes: data-element=R_Ext_dstVehTotMes.Ext_dstVehTotMes
          dr_Ext_nEng: data-element=R_Ext_nEng.Ext_nEng
          dr_Ext_bPush: data-element=R_Ext_bPush.Ext_bPush
          dr_Ext_stGBxCf: data-element=R_Ext_stGBxCf.Ext_stGBxCf
          dr_Ext_tAir: data-element=R_Ext_tAir.Ext_tAir
          dr_CoPtUH_stPwt: data-element=R_CoPtUH_stPwt.CoPtUH_stPwt
          dr_TqSys_nTarIdl: data-element=R_TqSys_nTarIdl.TqSys_nTarIdl
        7 x data send point:
          ds_CoPtUH_stSTTLightAcv: data-element=P_CoPtUH_stSTTLightAcv.CoPtUH_stSTTLightAcv
          ds_CoPtUH_bInfoAcvCluPed: data-element=P_CoPtUH_bInfoAcvCluPed.CoPtUH_bInfoAcvCluPed
          ds_CoPtUH_bInfoRdy: data-element=P_CoPtUH_bInfoRdy.CoPtUH_bInfoRdy
          ds_CoPtUH_bSTTInh: data-element=P_CoPtUH_bSTTInh.CoPtUH_bSTTInh
          ds_CoPtUH_bFbSpcFactSTTReq1: data-element=P_CoPtUH_bFbSpcFactSTTReq1.CoPtUH_bFbSpcFactSTTReq1
          dsp_CoPtUH_bAcvGSINeut: data-element=P_CoPtUH_bAcvGSINeut.CoPtUH_bAcvGSINeut
          ds_CoPtUH_bFbSpcFactSTTReq2: data-element=P_CoPtUH_bFbSpcFactSTTReq2.CoPtUH_bFbSpcFactSTTReq2
        7 x sync call:
          ssp_FRM_bAcvSTTLitCoPtUH: operation=R_FRM_bAcvSTTLitCoPtUH.GetFunctionPermission
          ssp_FRM_bAcvRStrtCoPtUH: operation=R_FRM_bAcvRStrtCoPtUH.GetFunctionPermission
          ssp_FRM_bInhStopCoPtUH: operation=R_FRM_bInhStopCoPtUH.GetFunctionPermission
          ssp_FRM_bAcvCutTotCoPtUH: operation=R_FRM_bAcvCutTotCoPtUH.GetFunctionPermission
          ssp_FRM_bAcvFastRStrtCoPtUH: operation=R_FRM_bAcvFastRStrtCoPtUH.GetFunctionPermission
          ssp_FRM_bInhPushCoPtUH: operation=R_FRM_bInhPushCoPtUH.GetFunctionPermission
          ssp_FRM_bAcvCutCoPtUH: operation=R_FRM_bAcvCutCoPtUH.GetFunctionPermission
      RE_CoStopStart_015_MSE: written-variable=[DgoFct_bHealDiagCfLvl1, DgoFct_bSTTOff, DgoFct_stRstrtReq]
        9 x data send point:
          ds_CoPtUH_bBltStopAuth: data-element=P_CoPtUH_bBltStopAuth.CoPtUH_bBltStopAuth
          ds_CoPtUH_bRStrtReqDgoBlt: data-element=P_CoPtUH_bRStrtReqDgoBlt.CoPtUH_bRStrtReqDgoBlt
          ds_CoPtUH_rMinCluRStrt: data-element=P_CoPtUH_rMinCluRStrt.CoPtUH_rMinCluRStrt
          ds_CoPtUH_stTestPosClu: data-element=P_CoPtUH_stTestPosClu.CoPtUH_stTestPosClu
          ds_CoPtUH_noGearTmpEnd: data-element=P_CoPtUH_noGearTmpEnd.CoPtUH_noGearTmpEnd
          ds_CoPtUH_noGearTmpBeg: data-element=P_CoPtUH_noGearTmpBeg.CoPtUH_noGearTmpBeg
          ds_CoPtUH_rMaxCluGc: data-element=P_CoPtUH_rMaxCluGc.CoPtUH_rMaxCluGc
          ds_CoPtUH_bTestPrvtBltAcv: data-element=P_CoPtUH_bTestPrvtBltAcv.CoPtUH_bTestPrvtBltAcv
          ds_CoPtUH_nEngClc: data-element=P_CoPtUH_nEngClc.CoPtUH_nEngClc
        sync call ssp_CoPtUH_LgEngRStrtInh: operation=R_CoPtUH_LgEngRStrtInh.SetEventStatus
      RE_CoStopStart_AftsNvramWrite_1
      RE_CoStopStart_013_MSE
        data send point ds_CoPtUH_stPwt: data-element=P_CoPtUH_stPwt.CoPtUH_stPwt
      RE_CoStopStart_014_TEV: read-variable=[MonDrv_bRstrtAntCncl, CoStop_bStopReq, CoRStrt_bRstrtReq, MgtEng_bLgRstrt]
        5 x data receive point:
          drp_CoPtUH_bEngStopReq: data-element=R_CoPtUH_bEngStopReq.CoPtUH_bEngStopReq
          dr_CoPtASE_stPwt: data-element=R_CoPtASE_stPwt.CoPtASE_stPwt
          dr_CoPtUH_bEngCutOffReq: data-element=R_CoPtUH_bEngCutOffReq.CoPtUH_bEngCutOffReq
          dr_CoSync_bDetNNull: data-element=R_CoSync_bDetNNull.CoSync_bDetNNull
          dr_CoPTStNew_stEng: data-element=R_CoPTStNew_stEng.CoPTStNew_stEng
        data send point ds_CoPtUH_stPwt: data-element=P_CoPtUH_stPwt.CoPtUH_stPwt
        sync call ssp_FRM_bAcvCutTotCoPtUH: operation=R_FRM_bAcvCutTotCoPtUH.GetFunctionPermission
        sync call ssp_FRM_bAcvRunCoPtUH: operation=R_FRM_bAcvRunCoPtUH.GetFunctionPermission
      RE_CoStopStart_017_MSE: written-variable=MgtAlt_bIntrAltRstrtReqRaw
        8 x data send point:
          ds_CoPtUH_bRStrtAnt: data-element=P_CoPtUH_bRStrtAnt.CoPtUH_bRStrtAnt
          ds_CoPtUH_bAltStallReq: data-element=P_CoPtUH_bAltStallReq.CoPtUH_bAltStallReq
          ds_CoPtUH_bAltRPosnEngReq: data-element=P_CoPtUH_bAltRPosnEngReq.CoPtUH_bAltRPosnEngReq
          ds_CoPtUH_bAltInh: data-element=P_CoPtUH_bAltInh.CoPtUH_bAltInh
          ds_CoPtUH_bCdnInhRStrt: data-element=P_CoPtUH_bCdnInhRStrt.CoPtUH_bCdnInhRStrt
          ds_CoPtUH_bAltRStrtReq: data-element=P_CoPtUH_bAltRStrtReq.CoPtUH_bAltRStrtReq
          ds_CoPtUH_bVSSNwAcvAuth: data-element=P_CoPtUH_bVSSNwAcvAuth.CoPtUH_bVSSNwAcvAuth
          ds_CoPtUH_bAltPrepRStrtReq: data-element=P_CoPtUH_bAltPrepRStrtReq.CoPtUH_bAltPrepRStrtReq
      RE_CoStopStart_003_MSE
        6 x data send point:
          ds_CoReqRStrt_stRStrtTyp: data-element=P_CoReqRStrt_stRStrtTyp.CoReqRStrt_stRStrtTyp
          ds_CoReqRStrt_bEngRStrtReq: data-element=P_CoReqRStrt_bEngRStrtReq.CoReqRStrt_bEngRStrtReq
          ds_CoReqRStrt_bRstrtAuth: data-element=P_CoReqRStrt_bRstrtAuth.CoReqRStrt_bRstrtAuth
          ds_CoReqRStrt_bAuthSA: data-element=P_CoReqRStrt_bAuthSA.CoReqRStrt_bAuthSA
          ds_CoReqRStrt_bEngStopAuth: data-element=P_CoReqRStrt_bEngStopAuth.CoReqRStrt_bEngStopAuth
          ds_CoReqRStrt_bNotBlsVehReq: data-element=P_CoReqRStrt_bNotBlsVehReq.CoReqRStrt_bNotBlsVehReq
      RE_CoStopStart_032_TEV: read-variable=MonGB_bRstrtAuth, written-variable=[MonVeh_bPresPtlRstrtReqForc, MonVeh_bStopAuth, MonVeh_stRstrtReq, MonVeh_bPtlVehRstrtReqForc, MonVeh_bOpDrvTraAuth, MonVeh_bHiSpdRstrtAuth, MonVeh_bInfoHillAsiDrvRstrt, MonVeh_bRstrtAuthMch, MonVeh_bRstrtAuth, MonVeh_bDeacHillAsi]
        24 x data receive point:
          dr_Ext_stGBxCf: data-element=R_Ext_stGBxCf.Ext_stGBxCf
          dr_TqSys_nTarIdl: data-element=R_TqSys_nTarIdl.TqSys_nTarIdl
          dr_CoReqCha_bHillAsiRdyEngStop: data-element=R_CoReqCha_bHillAsiRdyEngStop.CoReqCha_bHillAsiRdyEngStop
          dr_Ext_nEng: data-element=R_Ext_nEng.Ext_nEng
          dr_Ext_posnGBxLev: data-element=R_Ext_posnGBxLev.Ext_posnGBxLev
          dr_CoReqStg_stEngStopAuth: data-element=R_CoReqStg_stEngStopAuth.CoReqStg_stEngStopAuth
          dr_CoReqDmpr_stEngStopAuth: data-element=R_CoReqDmpr_stEngStopAuth.CoReqDmpr_stEngStopAuth
          dr_CoReqVeh_stEngStopAuth: data-element=R_CoReqVeh_stEngStopAuth.CoReqVeh_stEngStopAuth
          dr_PredEs_nFast: data-element=R_PredEs_nFast.PredEs_nFast
          dr_CoReqCha_bUncrtSlopStab: data-element=R_CoReqCha_bUncrtSlopStab.CoReqCha_bUncrtSlopStab
          dr_CoReqCha_bEngRStrtReq: data-element=R_CoReqCha_bEngRStrtReq.CoReqCha_bEngRStrtReq
          dr_Ext_pAirExtMes: data-element=R_Ext_pAirExtMes.Ext_pAirExtMes
          dr_CoReqStg_bEngRStrtReq: data-element=R_CoReqStg_bEngRStrtReq.CoReqStg_bEngRStrtReq
          dr_Ext_pBrkAsi: data-element=R_Ext_pBrkAsi.Ext_pBrkAsi
          dr_CoPtUH_stPwt: data-element=R_CoPtUH_stPwt.CoPtUH_stPwt
          dr_Ext_spdVehSecu: data-element=R_Ext_spdVehSecu.Ext_spdVehSecu
          dr_CoReqDmpr_bEngRStrtReq: data-element=R_CoReqDmpr_bEngRStrtReq.CoReqDmpr_bEngRStrtReq
          dr_Ext_pRelBrkAsi: data-element=R_Ext_pRelBrkAsi.Ext_pRelBrkAsi
          dr_CoReqVeh_stEngRStrtReq: data-element=R_CoReqVeh_stEngRStrtReq.CoReqVeh_stEngRStrtReq
          dr_CoReqCha_stEngStopAuth: data-element=R_CoReqCha_stEngStopAuth.CoReqCha_stEngStopAuth
          dr_CoPtUH_bFbSpcFactSTTReq1: data-element=R_CoPtUH_bFbSpcFactSTTReq1.CoPtUH_bFbSpcFactSTTReq1
          dr_Veh_spdVeh: data-element=R_Veh_spdVeh.Veh_spdVeh
          dr_CoReqCha_stEngRStrtInh: data-element=R_CoReqCha_stEngRStrtInh.CoReqCha_stEngRStrtInh
          dr_CoReqCha_rSlopStab: data-element=R_CoReqCha_rSlopStab.CoReqCha_rSlopStab
        5 x data send point:
          ds_CoPtUH_bStPresLo: data-element=P_CoPtUH_bStPresLo.CoPtUH_bStPresLo
          ds_CoPtUH_bStopAuthSlop: data-element=P_CoPtUH_bStopAuthSlop.CoPtUH_bStopAuthSlop
          ds_CoPtUH_bEngRstrtClsCluCdn: data-element=P_CoPtUH_bEngRstrtClsCluCdn.CoPtUH_bEngRstrtClsCluCdn
          ds_CoPtUH_pRelBrkAsi: data-element=P_CoPtUH_pRelBrkAsi.CoPtUH_pRelBrkAsi
          ds_CoPtUH_bInhHiSpdAltRstrtReq: data-element=P_CoPtUH_bInhHiSpdAltRstrtReq.CoPtUH_bInhHiSpdAltRstrtReq
        sync call ssp_FRM_bInhspdVehCoPtUH: operation=R_FRM_bInhspdVehCoPtUH.GetFunctionPermission
        sync call ssp_FRM_bInhRelBrkAsiCoPtUH: operation=R_FRM_bInhRelBrkAsiCoPtUH.GetFunctionPermission
      RE_CoStopStart_026_TEV: written-variable=[MonEE_stRstrtReq, MonEE_bStopAuth]
        5 x data receive point:
          dr_CoReqRStrt_bEngRStrtReq: data-element=R_CoReqRStrt_bEngRStrtReq.CoReqRStrt_bEngRStrtReq
          dr_CoEmSTT_stEngRStrtReq: data-element=R_CoEmSTT_stEngRStrtReq.CoEmSTT_stEngRStrtReq
          dr_CoEmSTT_stEngStopAuth: data-element=R_CoEmSTT_stEngStopAuth.CoEmSTT_stEngStopAuth
          dr_CoPtUH_bFbSpcFactSTTReq1: data-element=R_CoPtUH_bFbSpcFactSTTReq1.CoPtUH_bFbSpcFactSTTReq1
          dr_CoReqRStrt_bEngStopAuth: data-element=R_CoReqRStrt_bEngStopAuth.CoReqRStrt_bEngStopAuth
        data send point ds_CoPtUH_bCompTqRStrt: data-element=P_CoPtUH_bCompTqRStrt.CoPtUH_bCompTqRStrt
      RE_CoStopStart_030_TEV: written-variable=[MonGB_bCutCaseLgGc, MonGB_stRstrtReq, MonGB_bRstrtAuth, MonGB_bStopAuth, MonGB_bMAPRstrtAuth, MonGB_bRstrtTypATReq]
        12 x data receive point:
          dr_CoPtUH_bOpDrvTraReq: data-element=R_CoPtUH_bOpDrvTraReq.CoPtUH_bOpDrvTraReq
          dr_Ext_stTraTypCf: data-element=R_Ext_stTraTypCf.Ext_stTraTypCf
          dr_Ext_bNeut: data-element=R_Ext_bNeut.Ext_bNeut
          dr_Ext_posnGBxLev: data-element=R_Ext_posnGBxLev.Ext_posnGBxLev
          dr_Tra_noEgdGear: data-element=R_Tra_noEgdGear.Tra_noEgdGear
          dr_CoReqAMT_stEngStopAuth: data-element=R_CoReqAMT_stEngStopAuth.CoReqAMT_stEngStopAuth
          dr_CoPt_bInhEngStopProtManClu: data-element=R_CoPt_bInhEngStopProtManClu.CoPt_bInhEngStopProtManClu
          dr_Ext_bRStrtAuthTra: data-element=R_Ext_bRStrtAuthTra.Ext_bRStrtAuthTra
          dr_Ext_rCluPHiFreq: data-element=R_Ext_rCluPHiFreq.Ext_rCluPHiFreq
          dr_Tra_noTarGear: data-element=R_Tra_noTarGear.Tra_noTarGear
          dr_Ext_stGBxCf: data-element=R_Ext_stGBxCf.Ext_stGBxCf
          dr_CoReqAMT_bEngRStrtReq: data-element=R_CoReqAMT_bEngRStrtReq.CoReqAMT_bEngRStrtReq
        data send point ds_CoPtUH_bDrvTraOp: data-element=P_CoPtUH_bDrvTraOp.CoPtUH_bDrvTraOp
        data send point ds_CoPtUH_bRStrtMchAuth: data-element=P_CoPtUH_bRStrtMchAuth.CoPtUH_bRStrtMchAuth
        sync call ssp_FRM_bInhNeutCoPtUH: operation=R_FRM_bInhNeutCoPtUH.GetFunctionPermission
        sync call ssp_FRM_bInhCluPCoPtUH: operation=R_FRM_bInhCluPCoPtUH.GetFunctionPermission
      RE_CoStopStart_004_TEV
        26 x data receive point:
          dr_TqLimUH_stDrivTyp: data-element=R_TqLimUH_stDrivTyp.TqLimUH_stDrivTyp
          dr_Afts_bRstMemCoReqRStrt: data-element=R_Afts_bRstMemCoReqRStrt.Afts_bRstMemCoReqRStrt
          dr_CoOptmEl_stElEProv: data-element=R_CoOptmEl_stElEProv.CoOptmEl_stElEProv
          dr_CoPtSynt_stPwt: data-element=R_CoPtSynt_stPwt.CoPtSynt_stPwt
          dr_CoPtUH_bRstrtCritAuth: data-element=R_CoPtUH_bRstrtCritAuth.CoPtUH_bRstrtCritAuth
          dr_CoPtUH_bDrvTraOp: data-element=R_CoPtUH_bDrvTraOp.CoPtUH_bDrvTraOp
          dr_Ext_bNotAvl_resBattIt: data-element=R_Ext_bNotAvl_resBattIt.Ext_bNotAvl_resBattIt
          dr_CoEmCkg_stStrtRstrtFbCmd: data-element=R_CoEmCkg_stStrtRstrtFbCmd.CoEmCkg_stStrtRstrtFbCmd
          dr_BatMgt_resBattIt: data-element=R_BatMgt_resBattIt.BatMgt_resBattIt
          dr_PredEs_agUncrtEs: data-element=R_PredEs_agUncrtEs.PredEs_agUncrtEs
          dr_Ext_tCoMes: data-element=R_Ext_tCoMes.Ext_tCoMes
          dr_BatMgt_uBattOc: data-element=R_BatMgt_uBattOc.BatMgt_uBattOc
          dr_PredEs_nFast: data-element=R_PredEs_nFast.PredEs_nFast
          dr_VSSCtzMgt_uUcapMes: data-element=R_VSSCtzMgt_uUcapMes.VSSCtzMgt_uUcapMes
          dr_Veh_spdVeh: data-element=R_Veh_spdVeh.Veh_spdVeh
          dr_Ext_bNotAvl_uBattOc: data-element=R_Ext_bNotAvl_uBattOc.Ext_bNotAvl_uBattOc
          dr_PredRstrt_tiMax2TDC: data-element=R_PredRstrt_tiMax2TDC.PredRstrt_tiMax2TDC
          dr_Ext_tOilMes: data-element=R_Ext_tOilMes.Ext_tOilMes
          dr_CoSync_bDetNNull: data-element=R_CoSync_bDetNNull.CoSync_bDetNNull
          dr_PredEs_agEs: data-element=R_PredEs_agEs.PredEs_agEs
          dr_PredRstrt_noTDC: data-element=R_PredRstrt_noTDC.PredRstrt_noTDC
          dr_Sync_agEng: data-element=R_Sync_agEng.Sync_agEng
          dr_CoSync_bAgEsCfm: data-element=R_CoSync_bAgEsCfm.CoSync_bAgEsCfm
          dr_Ext_pAirExtMes: data-element=R_Ext_pAirExtMes.Ext_pAirExtMes
          dr_CoEmSTT_iElNwStop: data-element=R_CoEmSTT_iElNwStop.CoEmSTT_iElNwStop
          dr_RvAltMgt_tRvAltStatEstim: data-element=R_RvAltMgt_tRvAltStatEstim.RvAltMgt_tRvAltStatEstim
        6 x data send point:
          ds_CoReqRStrt_bRstrtAuth: data-element=P_CoReqRStrt_bRstrtAuth.CoReqRStrt_bRstrtAuth
          ds_CoReqRStrt_stRStrtTyp: data-element=P_CoReqRStrt_stRStrtTyp.CoReqRStrt_stRStrtTyp
          ds_CoReqRStrt_bEngRStrtReq: data-element=P_CoReqRStrt_bEngRStrtReq.CoReqRStrt_bEngRStrtReq
          ds_CoReqRStrt_bAuthSA: data-element=P_CoReqRStrt_bAuthSA.CoReqRStrt_bAuthSA
          ds_CoReqRStrt_bNotBlsVehReq: data-element=P_CoReqRStrt_bNotBlsVehReq.CoReqRStrt_bNotBlsVehReq
          ds_CoReqRStrt_bEngStopAuth: data-element=P_CoReqRStrt_bEngStopAuth.CoReqRStrt_bEngStopAuth
      RE_CoStopStart_AftsNvramRead_1
      RE_CoStopStart_011_MSE: written-variable=[CoStop_bStopAuthInfoRdy, CoStop_bStopReq]
        data send point ds_CoPtUH_bOpDrvTraReq: data-element=P_CoPtUH_bOpDrvTraReq.CoPtUH_bOpDrvTraReq
        data send point ds_CoPtUH_stTypSTTNotAvl: data-element=P_CoPtUH_stTypSTTNotAvl.CoPtUH_stTypSTTNotAvl
      RE_CoStopStart_012_TEV: read-variable=[MonEE_bStopAuth, MonEng_bStopAuth, MonVeh_bStopAuth, MonGB_bStopAuth, MonDrv_bStopAuth, MonVeh_bDeacHillAsi, MonDrv_bRstrtCritAuthAnt, MonVeh_bOpDrvTraAuth, MonDrv_bReqOpTraAT], written-variable=[CoStop_bStopAuthInfoRdy, CoStop_bStopReq]
        14 x data receive point:
          dr_CoPtUH_bCompTqRStrt: data-element=R_CoPtUH_bCompTqRStrt.CoPtUH_bCompTqRStrt
          dr_CoPtUH_stPwt: data-element=R_CoPtUH_stPwt.CoPtUH_stPwt
          dr_CoReqAMT_stEngStopAuth: data-element=R_CoReqAMT_stEngStopAuth.CoReqAMT_stEngStopAuth
          dr_CoPtASE_stPwt: data-element=R_CoPtASE_stPwt.CoPtASE_stPwt
          dr_CoReqDmpr_stEngStopAuth: data-element=R_CoReqDmpr_stEngStopAuth.CoReqDmpr_stEngStopAuth
          dr_Sfty_bInhEngStopSTTReq: data-element=R_Sfty_bInhEngStopSTTReq.Sfty_bInhEngStopSTTReq
          dr_CoReqVeh_stEngStopAuth: data-element=R_CoReqVeh_stEngStopAuth.CoReqVeh_stEngStopAuth
          dr_CoReqStg_stEngStopAuth: data-element=R_CoReqStg_stEngStopAuth.CoReqStg_stEngStopAuth
          dr_Veh_stDrvAvl: data-element=R_Veh_stDrvAvl.Veh_stDrvAvl
          dr_CoReqCha_stEngStopAuth: data-element=R_CoReqCha_stEngStopAuth.CoReqCha_stEngStopAuth
          dr_CoPtUH_bBltStopAuth: data-element=R_CoPtUH_bBltStopAuth.CoPtUH_bBltStopAuth
          dr_EngReqH_stEngStopAuth: data-element=R_EngReqH_stEngStopAuth.EngReqH_stEngStopAuth
          dr_Ext_stGBxCf: data-element=R_Ext_stGBxCf.Ext_stGBxCf
          dr_CoEmSTT_stEngStopAuth: data-element=R_CoEmSTT_stEngStopAuth.CoEmSTT_stEngStopAuth
        data send point ds_CoPtUH_bOpDrvTraReq: data-element=P_CoPtUH_bOpDrvTraReq.CoPtUH_bOpDrvTraReq
        data send point ds_CoPtUH_stTypSTTNotAvl: data-element=P_CoPtUH_stTypSTTNotAvl.CoPtUH_stTypSTTNotAvl
        data send point ds_CoPtUH_bRstrtCritAuth: data-element=P_CoPtUH_bRstrtCritAuth.CoPtUH_bRstrtCritAuth
        4 x sync call:
          ssp_FRM_bAcvFastRStrtCoPtUH: operation=R_FRM_bAcvFastRStrtCoPtUH.GetFunctionPermission
          ssp_FRM_bInhStopCoPtUH: operation=R_FRM_bInhStopCoPtUH.GetFunctionPermission
          ssp_FRM_bAcvCutCoPtUH: operation=R_FRM_bAcvCutCoPtUH.GetFunctionPermission
          ssp_FRM_bAcvRStrtCoPtUH: operation=R_FRM_bAcvRStrtCoPtUH.GetFunctionPermission
      RE_CoStopStart_008_TEV: read-variable=[MonDrv_bRstrtReq, DgoFct_bHealDiagCfLvl1, MonDrv_bRstrtAntCncl, MonVeh_bPtlVehRstrtReqForc, MonVeh_bPresPtlRstrtReqForc, MonVeh_bRstrtAuth, MonGB_bRstrtAuth, MonGB_bCutCaseLgGc, MgtDrv_bDftHld, MgtEng_bLgRstrt], written-variable=[CoCut_bRstrtFail, CoCut_ctRstrtFail, CoCut_ctForcRstrtFail, CoCut_bElMecIntrRstrt]
        14 x data receive point:
          dr_Ext_stGBxCf: data-element=R_Ext_stGBxCf.Ext_stGBxCf
          dr_CoSync_bStuckEngStaAcv: data-element=R_CoSync_bStuckEngStaAcv.CoSync_bStuckEngStaAcv
          dr_CoPtUH_bRStrtMchAuth: data-element=R_CoPtUH_bRStrtMchAuth.CoPtUH_bRStrtMchAuth
          dr_Ext_spdVehSecu: data-element=R_Ext_spdVehSecu.Ext_spdVehSecu
          dr_CoReqVeh_stEngRStrtReq: data-element=R_CoReqVeh_stEngRStrtReq.CoReqVeh_stEngRStrtReq
          dr_CoPtUH_bRStrtReqAvl: data-element=R_CoPtUH_bRStrtReqAvl.CoPtUH_bRStrtReqAvl
          dr_CoPtUH_stPwt: data-element=R_CoPtUH_stPwt.CoPtUH_stPwt
          dr_CoPtUH_stMaxRStrtReq: data-element=R_CoPtUH_stMaxRStrtReq.CoPtUH_stMaxRStrtReq
          dr_CoEmCkg_stStrtRstrtFbCmd: data-element=R_CoEmCkg_stStrtRstrtFbCmd.CoEmCkg_stStrtRstrtFbCmd
          dr_Ext_nEng: data-element=R_Ext_nEng.Ext_nEng
          dr_CoEmSTT_stEngRStrtReq: data-element=R_CoEmSTT_stEngRStrtReq.CoEmSTT_stEngRStrtReq
          dr_Veh_spdVeh: data-element=R_Veh_spdVeh.Veh_spdVeh
          dr_CoPtUH_bInhHiSpdAltRstrtReq: data-element=R_CoPtUH_bInhHiSpdAltRstrtReq.CoPtUH_bInhHiSpdAltRstrtReq
          dr_CoPTStNew_stEng: data-element=R_CoPTStNew_stEng.CoPTStNew_stEng
        15 x data send point:
          ds_CoPtUH_stBfBfLstRStrtFail: data-element=P_CoPtUH_stBfBfLstRStrtFail.CoPtUH_stBfBfLstRStrtFail
          ds_CoPtUH_bCutCaseRCfTyp3: data-element=P_CoPtUH_bCutCaseRCfTyp3.CoPtUH_bCutCaseRCfTyp3
          ds_CoPtUH_bCutCaseDgoBlt: data-element=P_CoPtUH_bCutCaseDgoBlt.CoPtUH_bCutCaseDgoBlt
          ds_CoPtUH_bEngStallReq: data-element=P_CoPtUH_bEngStallReq.CoPtUH_bEngStallReq
          ds_CoPtUH_bCutCaseAutRStrt: data-element=P_CoPtUH_bCutCaseAutRStrt.CoPtUH_bCutCaseAutRStrt
          ds_CoPtUH_bCutCaseNotRStrtAuth: data-element=P_CoPtUH_bCutCaseNotRStrtAuth.CoPtUH_bCutCaseNotRStrtAuth
          ds_CoPtUH_stBfLstRStrtFailCase: data-element=P_CoPtUH_stBfLstRStrtFailCase.CoPtUH_stBfLstRStrtFailCase
          ds_CoPtUH_bCutCaseClsTra: data-element=P_CoPtUH_bCutCaseClsTra.CoPtUH_bCutCaseClsTra
          ds_CoPtUH_bCutCaseLongGc: data-element=P_CoPtUH_bCutCaseLongGc.CoPtUH_bCutCaseLongGc
          ds_CoPtUH_bEngCutOffReq: data-element=P_CoPtUH_bEngCutOffReq.CoPtUH_bEngCutOffReq
          ds_CoPtUH_bCutCaseElMecRStrtReq: data-element=P_CoPtUH_bCutCaseElMecRStrtReq.CoPtUH_bCutCaseElMecRStrtReq
          ds_CoPtUH_bCutCaseRStrtReqForc: data-element=P_CoPtUH_bCutCaseRStrtReqForc.CoPtUH_bCutCaseRStrtReqForc
          ds_CoPtUH_stLstRStrtFailCase: data-element=P_CoPtUH_stLstRStrtFailCase.CoPtUH_stLstRStrtFailCase
          ds_CoPtUH_bCutCaseSpdMax: data-element=P_CoPtUH_bCutCaseSpdMax.CoPtUH_bCutCaseSpdMax
          ds_CoPtUH_bCutCaseVehRStrtReq: data-element=P_CoPtUH_bCutCaseVehRStrtReq.CoPtUH_bCutCaseVehRStrtReq
        4 x sync call:
          ssp_FRM_bAcvCutCoPtUH: operation=R_FRM_bAcvCutCoPtUH.GetFunctionPermission
          ssp_FRM_bInhspdVehCoPtUH: operation=R_FRM_bInhspdVehCoPtUH.GetFunctionPermission
          ssp_CoPtUH_CutReq: operation=R_CoPtUH_CutReq.SetEventStatus
          ssp_FRM_bAcvCutTotCoPtUH: operation=R_FRM_bAcvCutTotCoPtUH.GetFunctionPermission
      RE_CoStopStart_009_MSE: written-variable=CoRStrt_bRstrtReq
        data send point ds_CoPtUH_bRStrtTypAT: data-element=P_CoPtUH_bRStrtTypAT.CoPtUH_bRStrtTypAT
        data send point ds_CoPtUH_bRStrtReqAvl: data-element=P_CoPtUH_bRStrtReqAvl.CoPtUH_bRStrtReqAvl
        data send point ds_CoPtUH_stMaxRStrtReq: data-element=P_CoPtUH_stMaxRStrtReq.CoPtUH_stMaxRStrtReq
      RE_CoStopStart_016_TEV: read-variable=MonDrv_bRstrtReq, written-variable=[DgoFct_bHealDiagCfLvl1, DgoFct_bSTTOff, DgoFct_stRstrtReq]
        23 x data receive point:
          dr_CoReqCha_stEngRStrtInh: data-element=R_CoReqCha_stEngRStrtInh.CoReqCha_stEngRStrtInh
          dr_RvAltMgt_tqRvAltGenModMv: data-element=R_RvAltMgt_tqRvAltGenModMv.RvAltMgt_tqRvAltGenModMv
          dr_Ext_bPush: data-element=R_Ext_bPush.Ext_bPush
          dr_CoOptmEl_tqAlt: data-element=R_CoOptmEl_tqAlt.CoOptmEl_tqAlt
          dr_RvAltMgt_nRvAltMes: data-element=R_RvAltMgt_nRvAltMes.RvAltMgt_nRvAltMes
          dr_ECU_bWkuMain: data-element=R_ECU_bWkuMain.ECU_bWkuMain
          dr_CoReqCha_rSlopStab: data-element=R_CoReqCha_rSlopStab.CoReqCha_rSlopStab
          dr_Ext_stGBxCf: data-element=R_Ext_stGBxCf.Ext_stGBxCf
          dr_Tra_bGearManVld: data-element=R_Tra_bGearManVld.Tra_bGearManVld
          dr_TqSys_tqCkEngReal: data-element=R_TqSys_tqCkEngReal.TqSys_tqCkEngReal
          dr_Ext_rCluPHiFreq: data-element=R_Ext_rCluPHiFreq.Ext_rCluPHiFreq
          dr_CoPTStNew_stEng: data-element=R_CoPTStNew_stEng.CoPTStNew_stEng
          dr_Veh_spdVeh: data-element=R_Veh_spdVeh.Veh_spdVeh
          dr_RvAltMgt_nRvAltMv: data-element=R_RvAltMgt_nRvAltMv.RvAltMgt_nRvAltMv
          dr_TqLimUH_stDrivTyp: data-element=R_TqLimUH_stDrivTyp.TqLimUH_stDrivTyp
          dr_Ext_nEng: data-element=R_Ext_nEng.Ext_nEng
          dr_CoPtASE_stPwt: data-element=R_CoPtASE_stPwt.CoPtASE_stPwt
          dr_CoPtUH_stPwt: data-element=R_CoPtUH_stPwt.CoPtUH_stPwt
          dr_Ext_bNeut: data-element=R_Ext_bNeut.Ext_bNeut
          dr_CoPt_spdVehGearRatCord: data-element=R_CoPt_spdVehGearRatCord.CoPt_spdVehGearRatCord
          dr_TqSys_nTarIdl: data-element=R_TqSys_nTarIdl.TqSys_nTarIdl
          dr_Tra_noGearMan: data-element=R_Tra_noGearMan.Tra_noGearMan
          dr_RvAltMgt_tqRstrtMaxEstim: data-element=R_RvAltMgt_tqRstrtMaxEstim.RvAltMgt_tqRstrtMaxEstim
        9 x data send point:
          ds_CoPtUH_noGearTmpEnd: data-element=P_CoPtUH_noGearTmpEnd.CoPtUH_noGearTmpEnd
          ds_CoPtUH_stTestPosClu: data-element=P_CoPtUH_stTestPosClu.CoPtUH_stTestPosClu
          ds_CoPtUH_bBltStopAuth: data-element=P_CoPtUH_bBltStopAuth.CoPtUH_bBltStopAuth
          ds_CoPtUH_rMaxCluGc: data-element=P_CoPtUH_rMaxCluGc.CoPtUH_rMaxCluGc
          ds_CoPtUH_bRStrtReqDgoBlt: data-element=P_CoPtUH_bRStrtReqDgoBlt.CoPtUH_bRStrtReqDgoBlt
          ds_CoPtUH_rMinCluRStrt: data-element=P_CoPtUH_rMinCluRStrt.CoPtUH_rMinCluRStrt
          ds_CoPtUH_nEngClc: data-element=P_CoPtUH_nEngClc.CoPtUH_nEngClc
          ds_CoPtUH_bTestPrvtBltAcv: data-element=P_CoPtUH_bTestPrvtBltAcv.CoPtUH_bTestPrvtBltAcv
          ds_CoPtUH_noGearTmpBeg: data-element=P_CoPtUH_noGearTmpBeg.CoPtUH_noGearTmpBeg
        10 x sync call:
          ssp_CoPtUH_ORngGcClu: operation=R_CoPtUH_ORngGcClu.SetEventStatus
          ssp_FRM_bInhDgoCluNeutCoPtUH: operation=R_FRM_bInhDgoCluNeutCoPtUH.GetFunctionPermission
          ssp_CoPtUH_ORngGearMinClu: operation=R_CoPtUH_ORngGearMinClu.SetEventStatus
          ssp_CoPtUH_ORngGcNeut: operation=R_CoPtUH_ORngGcNeut.SetEventStatus
          ssp_CoPtUH_LgEngRStrtInh: operation=R_CoPtUH_LgEngRStrtInh.SetEventStatus
          ssp_FRM_bInhDgoBltCoPtUH: operation=R_FRM_bInhDgoBltCoPtUH.GetFunctionPermission
          ssp_CoPtUH_Blt: operation=R_CoPtUH_Blt.SetEventStatus
          ssp_CoPtUH_ORngGearEnaClu: operation=R_CoPtUH_ORngGearEnaClu.SetEventStatus
          ssp_CoPtUH_ORngGcMinClu: operation=R_CoPtUH_ORngGcMinClu.SetEventStatus
          ssp_CoPtUH_ORngGearNeut: operation=R_CoPtUH_ORngGearNeut.SetEventStatus
      RE_CoStopStart_025_MSE: written-variable=[MonEE_stRstrtReq, MonEE_bStopAuth]
        data send point ds_CoPtUH_bCompTqRStrt: data-element=P_CoPtUH_bCompTqRStrt.CoPtUH_bCompTqRStrt
      RE_CoStopStart_027_MSE: written-variable=[MonEng_stRstrtReq, MonEng_bStopEngRdy, MonEng_bStopAuth]
        data send point ds_CoPtUH_tiNbRstrtFreqLim: data-element=P_CoPtUH_tiNbRstrtFreqLim.CoPtUH_tiNbRstrtFreqLim
        data send point ds_CoPtUH_bLimFreqStopInh: data-element=P_CoPtUH_bLimFreqStopInh.CoPtUH_bLimFreqStopInh
      RE_CoStopStart_007_MSE: written-variable=[CoCut_ctRstrtFail, CoCut_ctForcRstrtFail, CoCut_bElMecIntrRstrt, CoCut_bRstrtFail]
        15 x data send point:
          ds_CoPtUH_bCutCaseAutRStrt: data-element=P_CoPtUH_bCutCaseAutRStrt.CoPtUH_bCutCaseAutRStrt
          ds_CoPtUH_bCutCaseVehRStrtReq: data-element=P_CoPtUH_bCutCaseVehRStrtReq.CoPtUH_bCutCaseVehRStrtReq
          ds_CoPtUH_bCutCaseRCfTyp3: data-element=P_CoPtUH_bCutCaseRCfTyp3.CoPtUH_bCutCaseRCfTyp3
          ds_CoPtUH_bCutCaseDgoBlt: data-element=P_CoPtUH_bCutCaseDgoBlt.CoPtUH_bCutCaseDgoBlt
          ds_CoPtUH_bCutCaseRStrtReqForc: data-element=P_CoPtUH_bCutCaseRStrtReqForc.CoPtUH_bCutCaseRStrtReqForc
          ds_CoPtUH_stBfBfLstRStrtFail: data-element=P_CoPtUH_stBfBfLstRStrtFail.CoPtUH_stBfBfLstRStrtFail
          ds_CoPtUH_bCutCaseNotRStrtAuth: data-element=P_CoPtUH_bCutCaseNotRStrtAuth.CoPtUH_bCutCaseNotRStrtAuth
          ds_CoPtUH_bCutCaseClsTra: data-element=P_CoPtUH_bCutCaseClsTra.CoPtUH_bCutCaseClsTra
          ds_CoPtUH_stBfLstRStrtFailCase: data-element=P_CoPtUH_stBfLstRStrtFailCase.CoPtUH_stBfLstRStrtFailCase
          ds_CoPtUH_bCutCaseLongGc: data-element=P_CoPtUH_bCutCaseLongGc.CoPtUH_bCutCaseLongGc
          ds_CoPtUH_bCutCaseSpdMax: data-element=P_CoPtUH_bCutCaseSpdMax.CoPtUH_bCutCaseSpdMax
          ds_CoPtUH_bEngCutOffReq: data-element=P_CoPtUH_bEngCutOffReq.CoPtUH_bEngCutOffReq
          ds_CoPtUH_bCutCaseElMecRStrtReq: data-element=P_CoPtUH_bCutCaseElMecRStrtReq.CoPtUH_bCutCaseElMecRStrtReq
          ds_CoPtUH_stLstRStrtFailCase: data-element=P_CoPtUH_stLstRStrtFailCase.CoPtUH_stLstRStrtFailCase
          ds_CoPtUH_bEngStallReq: data-element=P_CoPtUH_bEngStallReq.CoPtUH_bEngStallReq
      RE_CoStopStart_024_TEV: read-variable=[CoCut_ctRstrtFail, MonVeh_bInfoHillAsiDrvRstrt, CoRStrt_bRstrtReq, MonEng_bStopEngRdy], written-variable=[MonDrv_bGSIStopAuth, MonDrv_stRstrtReq, MonDrv_bRstrtAntCncl, MonDrv_bPrepInfoRdy, MonDrv_bRstrtCritAuthAnt, MonDrv_bReqOpTraAT, MonDrv_bPrepRstrtReq, MonDrv_bRstrtAntReq, MonDrv_bRstrtReq, MonDrv_bStopCdnChg, MonDrv_bStopAuthRaw, MonDrv_bStopAuth]
        22 x data receive point:
          dr_Cha_stEPB: data-element=R_Cha_stEPB.Cha_stEPB
          dr_AccP_rAccP: data-element=R_AccP_rAccP.AccP_rAccP
          dr_CoPtUH_bOpDrvTraReq: data-element=R_CoPtUH_bOpDrvTraReq.CoPtUH_bOpDrvTraReq
          dr_Veh_spdVeh: data-element=R_Veh_spdVeh.Veh_spdVeh
          dr_CoPtUH_stPwt: data-element=R_CoPtUH_stPwt.CoPtUH_stPwt
          dr_CoPtUH_stMaxRStrtReq: data-element=R_CoPtUH_stMaxRStrtReq.CoPtUH_stMaxRStrtReq
          dr_Ext_bEfcBrkPedPrss: data-element=R_Ext_bEfcBrkPedPrss.Ext_bEfcBrkPedPrss
          dr_CoPtUH_stSTTLightAcv: data-element=R_CoPtUH_stSTTLightAcv.CoPtUH_stSTTLightAcv
          dr_CoPTStNew_stEng: data-element=R_CoPTStNew_stEng.CoPTStNew_stEng
          dr_Ext_bNeut: data-element=R_Ext_bNeut.Ext_bNeut
          dr_CoPtUH_bFbSpcFactSTTReq1: data-element=R_CoPtUH_bFbSpcFactSTTReq1.CoPtUH_bFbSpcFactSTTReq1
          dr_CoPtUH_bSTTInh: data-element=R_CoPtUH_bSTTInh.CoPtUH_bSTTInh
          dr_Ext_pBrkMCT: data-element=R_Ext_pBrkMCT.Ext_pBrkMCT
          dr_Ext_stGBxCf: data-element=R_Ext_stGBxCf.Ext_stGBxCf
          dr_Ext_spdVehSecu: data-element=R_Ext_spdVehSecu.Ext_spdVehSecu
          dr_CoReqAMT_stEngStopAuth: data-element=R_CoReqAMT_stEngStopAuth.CoReqAMT_stEngStopAuth
          dr_Veh_stDrvAvl: data-element=R_Veh_stDrvAvl.Veh_stDrvAvl
          dr_Ext_rCluPHiFreq: data-element=R_Ext_rCluPHiFreq.Ext_rCluPHiFreq
          dr_Tra_stGBxMod: data-element=R_Tra_stGBxMod.Tra_stGBxMod
          dr_CoReqRStrt_stRStrtTyp: data-element=R_CoReqRStrt_stRStrtTyp.CoReqRStrt_stRStrtTyp
          dr_Ext_bRvs: data-element=R_Ext_bRvs.Ext_bRvs
          dr_Ext_posnGBxLev: data-element=R_Ext_posnGBxLev.Ext_posnGBxLev
        data send point ds_CoPtUH_bRecNotStop: data-element=P_CoPtUH_bRecNotStop.CoPtUH_bRecNotStop
        sync call ssp_FRM_bInhspdVehCoPtUH: operation=R_FRM_bInhspdVehCoPtUH.GetFunctionPermission
      RE_CoStopStart_021_MSE: written-variable=MgtEng_bLgRstrt
        7 x data send point:
          ds_CoPtUH_bEngRStrtReq: data-element=P_CoPtUH_bEngRStrtReq.CoPtUH_bEngRStrtReq
          ds_CoPtUH_stAftsRStrtSuc: data-element=P_CoPtUH_stAftsRStrtSuc.CoPtUH_stAftsRStrtSuc
          ds_CoPtUH_bLatchDrvCyc: data-element=P_CoPtUH_bLatchDrvCyc.CoPtUH_bLatchDrvCyc
          ds_CoPtUH_bEngStopReq: data-element=P_CoPtUH_bEngStopReq.CoPtUH_bEngStopReq
          ds_CoPtUH_stFbSpcFactRStrtSuc: data-element=P_CoPtUH_stFbSpcFactRStrtSuc.CoPtUH_stFbSpcFactRStrtSuc
          ds_CoPtUH_bCtlDmprAuth: data-element=P_CoPtUH_bCtlDmprAuth.CoPtUH_bCtlDmprAuth
          ds_CoPtUH_tiCmplStop: data-element=P_CoPtUH_tiCmplStop.CoPtUH_tiCmplStop
      RE_CoStopStart_018_TEV: read-variable=[MgtEng_bLgRstrt, MonVeh_bRstrtAuthMch, MonDrv_bPrepRstrtReq, MonVeh_bHiSpdRstrtAuth, CoRStrt_bRstrtReq, MonDrv_bRstrtAntCncl], written-variable=MgtAlt_bIntrAltRstrtReqRaw
        13 x data receive point:
          dr_Ext_spdVehSecu: data-element=R_Ext_spdVehSecu.Ext_spdVehSecu
          dr_PARM_bEngRstrtAutnAvl: data-element=R_PARM_bEngRstrtAutnAvl.PARM_bEngRstrtAutnAvl
          dr_CoReqRStrt_bAuthSA: data-element=R_CoReqRStrt_bAuthSA.CoReqRStrt_bAuthSA
          dr_EngReqH_bEngRStrtAutnAvl: data-element=R_EngReqH_bEngRStrtAutnAvl.EngReqH_bEngRStrtAutnAvl
          dr_Veh_spdVeh: data-element=R_Veh_spdVeh.Veh_spdVeh
          drp_TqLimUH_bAcvUnBlsEng: data-element=R_TqLimUH_bAcvUnBlsEng.TqLimUH_bAcvUnBlsEng
          dr_CoPtUH_bRStrtMchAuth: data-element=R_CoPtUH_bRStrtMchAuth.CoPtUH_bRStrtMchAuth
          dr_CoPTStNew_stEng: data-element=R_CoPTStNew_stEng.CoPTStNew_stEng
          dr_CoStrt_bStrtAuth: data-element=R_CoStrt_bStrtAuth.CoStrt_bStrtAuth
          dr_CoPtUH_stPwt: data-element=R_CoPtUH_stPwt.CoPtUH_stPwt
          dr_CoPtUH_stMaxRStrtReq: data-element=R_CoPtUH_stMaxRStrtReq.CoPtUH_stMaxRStrtReq
          dr_CoPtASE_stPwt: data-element=R_CoPtASE_stPwt.CoPtASE_stPwt
          dr_CoTqRStrt_bEngStrtSuc: data-element=R_CoTqRStrt_bEngStrtSuc.CoTqRStrt_bEngStrtSuc
        8 x data send point:
          ds_CoPtUH_bAltStallReq: data-element=P_CoPtUH_bAltStallReq.CoPtUH_bAltStallReq
          ds_CoPtUH_bAltInh: data-element=P_CoPtUH_bAltInh.CoPtUH_bAltInh
          ds_CoPtUH_bVSSNwAcvAuth: data-element=P_CoPtUH_bVSSNwAcvAuth.CoPtUH_bVSSNwAcvAuth
          ds_CoPtUH_bAltPrepRStrtReq: data-element=P_CoPtUH_bAltPrepRStrtReq.CoPtUH_bAltPrepRStrtReq
          ds_CoPtUH_bCdnInhRStrt: data-element=P_CoPtUH_bCdnInhRStrt.CoPtUH_bCdnInhRStrt
          ds_CoPtUH_bAltRStrtReq: data-element=P_CoPtUH_bAltRStrtReq.CoPtUH_bAltRStrtReq
          ds_CoPtUH_bAltRPosnEngReq: data-element=P_CoPtUH_bAltRPosnEngReq.CoPtUH_bAltRPosnEngReq
          ds_CoPtUH_bRStrtAnt: data-element=P_CoPtUH_bRStrtAnt.CoPtUH_bRStrtAnt
        sync call ssp_FRM_bInhspdVehCoPtUH: operation=R_FRM_bInhspdVehCoPtUH.GetFunctionPermission
      RE_CoStopStart_028_TEV: written-variable=[MonEng_stRstrtReq, MonEng_bStopAuth, MonEng_bStopEngRdy]
        7 x data receive point:
          dr_CoPt_tqIdcReqCord_nRegReq: data-element=R_CoPt_tqIdcReqCord_nRegReq.CoPt_tqIdcReqCord_nRegReq
          dr_EngReqH_stEngStopAuth: data-element=R_EngReqH_stEngStopAuth.EngReqH_stEngStopAuth
          dr_Veh_spdVeh: data-element=R_Veh_spdVeh.Veh_spdVeh
          dr_CoPtUH_bFbSpcFactSTTReq1: data-element=R_CoPtUH_bFbSpcFactSTTReq1.CoPtUH_bFbSpcFactSTTReq1
          dr_CoPTStNew_stEng: data-element=R_CoPTStNew_stEng.CoPTStNew_stEng
          dr_Afts_bInhIniRunReq: data-element=R_Afts_bInhIniRunReq.Afts_bInhIniRunReq
          dr_EngReqH_bEngRunReq: data-element=R_EngReqH_bEngRunReq.EngReqH_bEngRunReq
        data send point ds_CoPtUH_bLimFreqStopInh: data-element=P_CoPtUH_bLimFreqStopInh.CoPtUH_bLimFreqStopInh
        data send point ds_CoPtUH_tiNbRstrtFreqLim: data-element=P_CoPtUH_tiNbRstrtFreqLim.CoPtUH_tiNbRstrtFreqLim
      RE_CoStopStart_010_TEV: read-variable=[MonDrv_bRstrtReq, MonVeh_stRstrtReq, MonGB_bRstrtTypATReq, MonEng_stRstrtReq, MonDrv_bRstrtAntReq, MonGB_stRstrtReq, MonVeh_bRstrtAuth, MonDrv_stRstrtReq, MonGB_bMAPRstrtAuth, DgoFct_stRstrtReq, MonGB_bRstrtAuth, MonEE_stRstrtReq], written-variable=CoRStrt_bRstrtReq
        5 x data receive point:
          dr_CoPtUH_stPwt: data-element=R_CoPtUH_stPwt.CoPtUH_stPwt
          dr_Ext_spdVehSecu: data-element=R_Ext_spdVehSecu.Ext_spdVehSecu
          dr_Veh_spdVeh: data-element=R_Veh_spdVeh.Veh_spdVeh
          dr_Ext_stGBxCf: data-element=R_Ext_stGBxCf.Ext_stGBxCf
          dr_Ext_tOilGBx: data-element=R_Ext_tOilGBx.Ext_tOilGBx
        data send point ds_CoPtUH_bRStrtReqAvl: data-element=P_CoPtUH_bRStrtReqAvl.CoPtUH_bRStrtReqAvl
        data send point ds_CoPtUH_stMaxRStrtReq: data-element=P_CoPtUH_stMaxRStrtReq.CoPtUH_stMaxRStrtReq
        data send point ds_CoPtUH_bRStrtTypAT: data-element=P_CoPtUH_bRStrtTypAT.CoPtUH_bRStrtTypAT
        sync call ssp_FRM_bAcvFastRStrtCoPtUH: operation=R_FRM_bAcvFastRStrtCoPtUH.GetFunctionPermission
        sync call ssp_FRM_bAcvRStrtCoPtUH: operation=R_FRM_bAcvRStrtCoPtUH.GetFunctionPermission
        sync call ssp_FRM_bInhspdVehCoPtUH: operation=R_FRM_bInhspdVehCoPtUH.GetFunctionPermission
      RE_CoStopStart_022_TEV: read-variable=[MgtDrv_bRiseSpcFacSTTReq1, CoRStrt_bRstrtReq, MonDrv_bRstrtAntCncl, CoCut_ctRstrtFail, CoCut_bRstrtFail, MgtAlt_bIntrAltRstrtReqRaw, CoCut_bElMecIntrRstrt], written-variable=MgtEng_bLgRstrt
        15 x data receive point:
          dr_CoPtUH_bFbSpcFactSTTReq1: data-element=R_CoPtUH_bFbSpcFactSTTReq1.CoPtUH_bFbSpcFactSTTReq1
          dr_Ext_bNeut: data-element=R_Ext_bNeut.Ext_bNeut
          dr_PARM_bEngRstrtAutnAvl: data-element=R_PARM_bEngRstrtAutnAvl.PARM_bEngRstrtAutnAvl
          dr_Ext_posnGBxLev: data-element=R_Ext_posnGBxLev.Ext_posnGBxLev
          dr_CoPtUH_bEngRstrtClsCluCdn: data-element=R_CoPtUH_bEngRstrtClsCluCdn.CoPtUH_bEngRstrtClsCluCdn
          dr_Ext_nEng: data-element=R_Ext_nEng.Ext_nEng
          dr_CoEmCkg_stStrtRstrtFbCmd: data-element=R_CoEmCkg_stStrtRstrtFbCmd.CoEmCkg_stStrtRstrtFbCmd
          dr_CoPtUH_bAltRStrtReq: data-element=R_CoPtUH_bAltRStrtReq.CoPtUH_bAltRStrtReq
          dr_CoTqRStrt_bEngStrtSuc: data-element=R_CoTqRStrt_bEngStrtSuc.CoTqRStrt_bEngStrtSuc
          dr_Ext_stGBxCf: data-element=R_Ext_stGBxCf.Ext_stGBxCf
          dr_CoPtUH_bStPresLo: data-element=R_CoPtUH_bStPresLo.CoPtUH_bStPresLo
          dr_CoPtUH_stPwt: data-element=R_CoPtUH_stPwt.CoPtUH_stPwt
          dr_EngReqH_bEngRStrtAutnAvl: data-element=R_EngReqH_bEngRStrtAutnAvl.EngReqH_bEngRStrtAutnAvl
          dr_CoTqRStrt_bTraTqAuthRaw: data-element=R_CoTqRStrt_bTraTqAuthRaw.CoTqRStrt_bTraTqAuthRaw
          dr_Ext_dstVehTotMes: data-element=R_Ext_dstVehTotMes.Ext_dstVehTotMes
        7 x data send point:
          ds_CoPtUH_stFbSpcFactRStrtSuc: data-element=P_CoPtUH_stFbSpcFactRStrtSuc.CoPtUH_stFbSpcFactRStrtSuc
          ds_CoPtUH_tiCmplStop: data-element=P_CoPtUH_tiCmplStop.CoPtUH_tiCmplStop
          ds_CoPtUH_bLatchDrvCyc: data-element=P_CoPtUH_bLatchDrvCyc.CoPtUH_bLatchDrvCyc
          ds_CoPtUH_bEngStopReq: data-element=P_CoPtUH_bEngStopReq.CoPtUH_bEngStopReq
          ds_CoPtUH_bCtlDmprAuth: data-element=P_CoPtUH_bCtlDmprAuth.CoPtUH_bCtlDmprAuth
          ds_CoPtUH_bEngRStrtReq: data-element=P_CoPtUH_bEngRStrtReq.CoPtUH_bEngRStrtReq
          ds_CoPtUH_stAftsRStrtSuc: data-element=P_CoPtUH_stAftsRStrtSuc.CoPtUH_stAftsRStrtSuc
        sync call ssp_FRM_bInhCtlDmprAuth: operation=R_FRM_bInhCtlDmprAuth.GetFunctionPermission
      RE_CoStopStart_031_MSE: written-variable=[MonVeh_bStopAuth, MonVeh_bRstrtAuthMch, MonVeh_bHiSpdRstrtAuth, MonVeh_bDeacHillAsi, MonVeh_bRstrtAuth, MonVeh_bPtlVehRstrtReqForc, MonVeh_bPresPtlRstrtReqForc, MonVeh_bOpDrvTraAuth, MonVeh_bInfoHillAsiDrvRstrt, MonVeh_stRstrtReq]
        5 x data send point:
          ds_CoPtUH_bStPresLo: data-element=P_CoPtUH_bStPresLo.CoPtUH_bStPresLo
          ds_CoPtUH_bInhHiSpdAltRstrtReq: data-element=P_CoPtUH_bInhHiSpdAltRstrtReq.CoPtUH_bInhHiSpdAltRstrtReq
          ds_CoPtUH_bEngRstrtClsCluCdn: data-element=P_CoPtUH_bEngRstrtClsCluCdn.CoPtUH_bEngRstrtClsCluCdn
          ds_CoPtUH_bStopAuthSlop: data-element=P_CoPtUH_bStopAuthSlop.CoPtUH_bStopAuthSlop
          ds_CoPtUH_pRelBrkAsi: data-element=P_CoPtUH_pRelBrkAsi.CoPtUH_pRelBrkAsi
  swc implementation Imp_CoStopStart: programming-language=C, behavior=IB_CoStopStart
    code-descriptors:
      code CodeDescriptor: type=SRC
        64 x xfile:
          CoStopStart_022_calibrations_h: url=CoStopStart_022_calibrations.h
          CoStopStart_030_calibrations_h: url=CoStopStart_030_calibrations.h
          CoStopStart_016_calibrations_h: url=CoStopStart_016_calibrations.h
          CoStopStart_024_TEV_fct_h: url=CoStopStart_024_TEV_fct.h
          CoStopStart_026_calibrations_h: url=CoStopStart_026_calibrations.h
          CoStopStart_020_calibrations_h: url=CoStopStart_020_calibrations.h
          CoStopStart_024_calibrations_h: url=CoStopStart_024_calibrations.h
          CoStopStart_030_calibrations_c: url=CoStopStart_030_calibrations.c
          CoStopStart_008_TEV_fct_h: url=CoStopStart_008_TEV_fct.h
          CoStopStart_010_TEV_fct_c: url=CoStopStart_010_TEV_fct.c
          CoStopStart_026_calibrations_c: url=CoStopStart_026_calibrations.c
          CoStopStart_004_calibrations_h: url=CoStopStart_004_calibrations.h
          CoStopStart_028_TEV_fct_h: url=CoStopStart_028_TEV_fct.h
          CoStopStart_032_TEV_fct_c: url=CoStopStart_032_TEV_fct.c
          CoStopStart_024_TEV_fct_c: url=CoStopStart_024_TEV_fct.c
          CoStopStart_020_calibrations_c: url=CoStopStart_020_calibrations.c
          CoStopStart_028_TEV_fct_c: url=CoStopStart_028_TEV_fct.c
          CoStopStart_014_calibrations_h: url=CoStopStart_014_calibrations.h
          CoStopStart_004_TEV_fct_c: url=CoStopStart_004_TEV_fct.c
          CoStopStart_032_calibrations_h: url=CoStopStart_032_calibrations.h
          CoStopStart_calibrations_h: url=CoStopStart_calibrations.h
          CoStopStart_012_calibrations_c: url=CoStopStart_012_calibrations.c
          CoStopStart_028_calibrations_c: url=CoStopStart_028_calibrations.c
          CoStopStart_012_calibrations_h: url=CoStopStart_012_calibrations.h
          CoStopStart_nvm_h: url=CoStopStart_nvm.h
          CoStopStart_024_calibrations_c: url=CoStopStart_024_calibrations.c
          CoStopStart_018_TEV_fct_h: url=CoStopStart_018_TEV_fct.h
          CoStopStart_032_calibrations_c: url=CoStopStart_032_calibrations.c
          CoStopStart_010_calibrations_h: url=CoStopStart_010_calibrations.h
          CoStopStart_010_calibrations_c: url=CoStopStart_010_calibrations.c
          CoStopStart_032_TEV_fct_h: url=CoStopStart_032_TEV_fct.h
          CoStopStart_004_TEV_fct_h: url=CoStopStart_004_TEV_fct.h
          CoStopStart_014_calibrations_c: url=CoStopStart_014_calibrations.c
          CoStopStart_012_TEV_fct_c: url=CoStopStart_012_TEV_fct.c
          CoStopStart_022_calibrations_c: url=CoStopStart_022_calibrations.c
          CoStopStart_028_calibrations_h: url=CoStopStart_028_calibrations.h
          CoStopStart_020_TEV_fct_c: url=CoStopStart_020_TEV_fct.c
          CoStopStart_026_TEV_fct_c: url=CoStopStart_026_TEV_fct.c
          CoStopStart_008_calibrations_h: url=CoStopStart_008_calibrations.h
          CoStopStart_008_calibrations_c: url=CoStopStart_008_calibrations.c
          CoStopStart_008_TEV_fct_c: url=CoStopStart_008_TEV_fct.c
          CoStopStart_014_TEV_fct_h: url=CoStopStart_014_TEV_fct.h
          CoStopStart_020_TEV_fct_h: url=CoStopStart_020_TEV_fct.h
          CoStopStart_MemMap_h: url=CoStopStart_MemMap.h
          CoStopStart_030_TEV_fct_h: url=CoStopStart_030_TEV_fct.h
          CoStopStart_h: url=CoStopStart.h
          CoStopStart_c: url=CoStopStart.c
          CoStopStart_022_TEV_fct_c: url=CoStopStart_022_TEV_fct.c
          CoStopStart_010_TEV_fct_h: url=CoStopStart_010_TEV_fct.h
          CoStopStart_018_TEV_fct_c: url=CoStopStart_018_TEV_fct.c
          CoStopStart_calibrations_c: url=CoStopStart_calibrations.c
          CoStopStart_004_calibrations_c: url=CoStopStart_004_calibrations.c
          CoStopStart_030_TEV_fct_c: url=CoStopStart_030_TEV_fct.c
          CoStopStart_016_TEV_fct_h: url=CoStopStart_016_TEV_fct.h
          CoStopStart_026_TEV_fct_h: url=CoStopStart_026_TEV_fct.h
          CoStopStart_016_TEV_fct_c: url=CoStopStart_016_TEV_fct.c
          CoStopStart_afts_c: url=CoStopStart_afts.c
          CoStopStart_018_calibrations_c: url=CoStopStart_018_calibrations.c
          CoStopStart_014_TEV_fct_c: url=CoStopStart_014_TEV_fct.c
          CoStopStart_022_TEV_fct_h: url=CoStopStart_022_TEV_fct.h
          CoStopStart_012_TEV_fct_h: url=CoStopStart_012_TEV_fct.h
          CoStopStart_nvm_c: url=CoStopStart_nvm.c
          CoStopStart_016_calibrations_c: url=CoStopStart_016_calibrations.c
          CoStopStart_018_calibrations_h: url=CoStopStart_018_calibrations.h
package /Components/SWC_CoStopStart/CoStopStart_IRVDatatypes
  39 x boolean type, all with base-type=boolean:
    DT_CoCut_bElMecIntrRstrt
    DT_CoCut_bRstrtFail
    DT_CoRStrt_bRstrtReq
    DT_CoStop_bStopAuthInfoRdy
    DT_CoStop_bStopReq
    DT_DgoFct_bHealDiagCfLvl1
    DT_DgoFct_bSTTOff
    DT_MgtAlt_bIntrAltRstrtReqRaw
    DT_MgtDrv_bDftHld
    DT_MgtDrv_bRiseSpcFacSTTReq1
    DT_MgtEng_bLgRstrt
    DT_MonDrv_bGSIStopAuth
    DT_MonDrv_bPrepInfoRdy
    DT_MonDrv_bPrepRstrtReq
    DT_MonDrv_bReqOpTraAT
    DT_MonDrv_bRstrtAntCncl
    DT_MonDrv_bRstrtAntReq
    DT_MonDrv_bRstrtCritAuthAnt
    DT_MonDrv_bRstrtReq
    DT_MonDrv_bStopAuth
    DT_MonDrv_bStopAuthRaw
    DT_MonDrv_bStopCdnChg
    DT_MonEE_bStopAuth
    DT_MonEng_bStopAuth
    DT_MonEng_bStopEngRdy
    DT_MonGB_bCutCaseLgGc
    DT_MonGB_bMAPRstrtAuth
    DT_MonGB_bRstrtAuth
    DT_MonGB_bRstrtTypATReq
    DT_MonGB_bStopAuth
    DT_MonVeh_bDeacHillAsi
    DT_MonVeh_bHiSpdRstrtAuth
    DT_MonVeh_bInfoHillAsiDrvRstrt
    DT_MonVeh_bOpDrvTraAuth
    DT_MonVeh_bPresPtlRstrtReqForc
    DT_MonVeh_bPtlVehRstrtReqForc
    DT_MonVeh_bRstrtAuth
    DT_MonVeh_bRstrtAuthMch
    DT_MonVeh_bStopAuth
  8 x integer type, all with base-type=uint8, lower-limit=0, upper-limit=255:
    DT_CoCut_ctForcRstrtFail
    DT_CoCut_ctRstrtFail
    DT_DgoFct_stRstrtReq
    DT_MonDrv_stRstrtReq
    DT_MonEE_stRstrtReq
    DT_MonEng_stRstrtReq
    DT_MonGB_stRstrtReq
    DT_MonVeh_stRstrtReq
